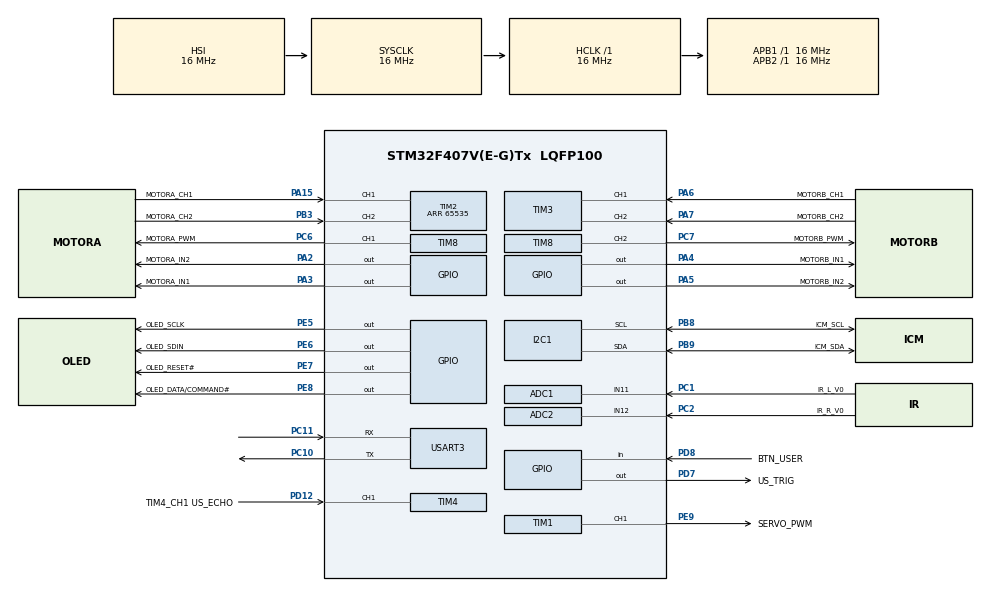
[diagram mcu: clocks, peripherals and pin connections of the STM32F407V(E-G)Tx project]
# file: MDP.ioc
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ADC1.Channel-1\#ChannelRegularConversion=ADC_CHANNEL_11
ADC1.NbrOfConversionFlag=1
ADC1.Rank-1\#ChannelRegularConversion=1
ADC1.SamplingTime-1\#ChannelRegularConversion=ADC_SAMPLETIME_3CYCLES
ADC1.master=1
ADC2.Channel-1\#ChannelRegularConversion=ADC_CHANNEL_12
ADC2.NbrOfConversionFlag=1
ADC2.Rank-1\#ChannelRegularConversion=1
ADC2.SamplingTime-1\#ChannelRegularConversion=ADC_SAMPLETIME_3CYCLES
I2C1.I2C_Mode=I2C_Fast
I2C1.NoStretchMode=I2C_NOSTRETCH_DISABLE
Mcu.Family=STM32F4
Mcu.Name=STM32F407V(E-G)Tx
Mcu.Package=LQFP100
NVIC.ADC_IRQn=true\:0\:0\:false\:false\:true\:true\:true\:true
NVIC.PriorityGroup=NVIC_PRIORITYGROUP_4
NVIC.TIM1_CC_IRQn=true\:0\:0\:false\:false\:true\:true\:true\:true
NVIC.TIM4_IRQn=true\:0\:0\:false\:false\:true\:true\:true\:true
NVIC.TIM7_IRQn=true\:0\:0\:false\:false\:true\:true\:true\:true
NVIC.USART3_IRQn=true\:0\:0\:false\:false\:true\:true\:true\:true
PA13.Signal=SYS_JTMS-SWDIO
PA14.Signal=SYS_JTCK-SWCLK
PA15.GPIO_Label=MOTORA_CH1
PA15.Signal=S_TIM2_CH1_ETR
PA2.GPIO_Label=MOTORA_IN2
PA2.Signal=GPIO_Output
PA3.GPIO_Label=MOTORA_IN1
PA3.Signal=GPIO_Output
PA4.GPIO_Label=MOTORB_IN1
PA4.Signal=GPIO_Output
PA5.GPIO_Label=MOTORB_IN2
PA5.Signal=GPIO_Output
PA6.GPIO_Label=MOTORB_CH1
PA6.Signal=S_TIM3_CH1
PA7.GPIO_Label=MOTORB_CH2
PA7.Signal=S_TIM3_CH2
PB3.GPIO_Label=MOTORA_CH2
PB3.Signal=S_TIM2_CH2
PB8.GPIO_Label=ICM_SCL
PB8.Mode=I2C
PB8.Signal=I2C1_SCL
PB9.GPIO_Label=ICM_SDA
PB9.Mode=I2C
PB9.Signal=I2C1_SDA
PC1.GPIO_Label=IR_L_V0
PC1.Signal=ADCx_IN11
PC10.Mode=Asynchronous
PC10.Signal=USART3_TX
PC11.Mode=Asynchronous
PC11.Signal=USART3_RX
PC2.GPIO_Label=IR_R_V0
PC2.Signal=ADCx_IN12
PC6.GPIO_Label=MOTORA_PWM
PC6.Signal=S_TIM8_CH1
PC7.GPIO_Label=MOTORB_PWM
PC7.Signal=S_TIM8_CH2
PD12.GPIO_Label=TIM4_CH1 US_ECHO
PD12.Signal=S_TIM4_CH1
PD7.GPIO_Label=US_TRIG
PD7.Signal=GPIO_Output
PD8.GPIO_Label=BTN_USER
PD8.GPIO_PuPd=GPIO_PULLUP
PD8.Signal=GPIO_Input
PE5.GPIO_Label=OLED_SCLK
PE5.Signal=GPIO_Output
PE6.GPIO_Label=OLED_SDIN
PE6.Signal=GPIO_Output
PE7.GPIO_Label=OLED_RESET\#
PE7.Signal=GPIO_Output
PE8.GPIO_Label=OLED_DATA/COMMAND\#
PE8.Signal=GPIO_Output
PE9.GPIO_Label=SERVO_PWM
PE9.Signal=S_TIM1_CH1
ProjectManager.HeapSize=0x200
ProjectManager.StackSize=0x400
ProjectManager.TargetToolchain=STM32CubeIDE
RCC.AHBFreq_Value=16000000
RCC.APB1Freq_Value=16000000
RCC.APB2Freq_Value=16000000
RCC.APB2TimFreq_Value=16000000
RCC.CortexFreq_Value=16000000
RCC.HSE_VALUE=25000000
RCC.HSI_VALUE=16000000
RCC.LSE_VALUE=32768
RCC.SYSCLKFreq_VALUE=16000000
RCC.VCOOutputFreq_Value=192000000
SH.ADCx_IN11.0=ADC1_IN11,IN11
SH.ADCx_IN12.0=ADC2_IN12,IN12
SH.S_TIM1_CH1.0=TIM1_CH1,PWM Generation1 CH1
SH.S_TIM2_CH1_ETR.0=TIM2_CH1,Encoder_Interface
SH.S_TIM2_CH2.0=TIM2_CH2,Encoder_Interface
SH.S_TIM3_CH1.0=TIM3_CH1,Encoder_Interface
SH.S_TIM3_CH2.0=TIM3_CH2,Encoder_Interface
SH.S_TIM4_CH1.0=TIM4_CH1,Input_Capture1_from_TI1
SH.S_TIM8_CH1.0=TIM8_CH1,PWM Generation1 CH1
SH.S_TIM8_CH2.0=TIM8_CH2,PWM Generation2 CH2
TIM1.Channel-PWM\ Generation1\ CH1=TIM_CHANNEL_1
TIM1.CounterMode=TIM_COUNTERMODE_UP
TIM1.OCMode_PWM-PWM\ Generation1\ CH1=TIM_OCMODE_PWM1
TIM1.Period=64000-1
TIM1.Prescaler=5-1
TIM2.EncoderMode=TIM_ENCODERMODE_TI12
TIM2.IC1Polarity=TIM_ICPOLARITY_RISING
TIM2.IC2Polarity=TIM_ICPOLARITY_RISING
TIM2.Period=65535
TIM3.EncoderMode=TIM_ENCODERMODE_TI12
TIM3.IC1Filter=0
TIM3.IC1Polarity=TIM_ICPOLARITY_RISING
TIM3.IC2Filter=0
TIM3.IC2Polarity=TIM_ICPOLARITY_RISING
TIM4.Channel-Input_Capture1_from_TI1=TIM_CHANNEL_1
TIM4.Period=65536-1
TIM4.Prescaler=16-1
TIM6.Period=65536-1
TIM6.Prescaler=16-1
TIM7.Period=16000-1
TIM7.Prescaler=2-1
TIM8.Channel-PWM\ Generation1\ CH1=TIM_CHANNEL_1
TIM8.Channel-PWM\ Generation2\ CH2=TIM_CHANNEL_2
TIM8.Period=7200-1
USART3.VirtualMode=VM_ASYNC
VP_TIM1_VS_ClockSourceINT.Mode=Internal
VP_TIM4_VS_ClockSourceINT.Mode=Internal
VP_TIM6_VS_ClockSourceINT.Mode=Enable_Timer
VP_TIM7_VS_ClockSourceINT.Mode=Enable_Timer
VP_TIM8_VS_ClockSourceINT.Mode=Internal
board=custom

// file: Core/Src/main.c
/* USER CODE BEGIN Header */
/**
  ******************************************************************************
  * @file           : main.c
  * @brief          : Main program body
  ******************************************************************************
  * @attention
  *
  * Copyright (c) 2024 STMicroelectronics.
  * All rights reserved.
  *
  * This software is licensed under terms that can be found in the LICENSE file
  * in the root directory of this software component.
  * If no LICENSE file comes with this software, it is provided AS-IS.
  *
  ******************************************************************************
  */
/* USER CODE END Header */
#include "main.h"

/* USER CODE BEGIN Includes */
#include <stdlib.h>
#include <math.h>
#include "commands.h"
#include "dist.h"
#include "angle.h"
#include "delay_us.h"
#include "oled.h"
#include "sensors.h"
#include "motor.h"
#include "servo.h"
/* USER CODE END Includes */

/* USER CODE BEGIN PD */
//8MHz / 16000 = 2.0ms frame.
#define MS_FRAME 2.0f
#define SERIAL_BUF_SIZE 20
#define SERIAL_RING_SIZE 1000
#define DIST_DIFF_DEFAULT 50
#define BRAKE_SPEED 20
#define TICKS_ES_MAX 10
#define PI 3.14159265359
#define DEG_TO_RAD 180 / PI
/* USER CODE END PD */

ADC_HandleTypeDef hadc1;
ADC_HandleTypeDef hadc2;

I2C_HandleTypeDef hi2c1;

TIM_HandleTypeDef htim1;
TIM_HandleTypeDef htim2;
TIM_HandleTypeDef htim3;
TIM_HandleTypeDef htim4;
TIM_HandleTypeDef htim6;
TIM_HandleTypeDef htim7;
TIM_HandleTypeDef htim8;

UART_HandleTypeDef huart3;

/* USER CODE BEGIN PV */
//sensors variables.
Sensors sensors;
MagCalParams magCalParams;

//serial buffers.
volatile uint16_t ring_i = 0, track_i = 0;
uint16_t buf_i = 0;

uint8_t buf_serial[SERIAL_BUF_SIZE];
uint8_t ring_serial[SERIAL_RING_SIZE];

//ultrasound pulse width measurement.
volatile uint8_t isRisingCaptured = 0;
volatile uint8_t usCaptureComplete = 0;
volatile uint16_t usWrap = 0;
volatile uint32_t counter;

//paced loop.
volatile uint8_t newTick = 0;
/* USER CODE END PV */

void SystemClock_Config(void);
static void MX_GPIO_Init(void);
static void MX_USART3_UART_Init(void);
static void MX_I2C1_Init(void);
static void MX_TIM8_Init(void);
static void MX_TIM2_Init(void);
static void MX_TIM3_Init(void);
static void MX_TIM1_Init(void);
static void MX_TIM4_Init(void);
static void MX_ADC1_Init(void);
static void MX_TIM6_Init(void);
static void MX_TIM7_Init(void);
static void MX_ADC2_Init(void);

/* USER CODE BEGIN 0 */

//increment index in a ring.
static void serial_inc_ring(volatile uint16_t *i) {
	*i = (*i + 1) % SERIAL_RING_SIZE;
}

//serial in.
void HAL_UART_RxCpltCallback(UART_HandleTypeDef *huart) {
	serial_inc_ring(&ring_i);
	HAL_UART_Receive_IT(&huart3, &ring_serial[ring_i], 1);
}

/* --- Start: Timer Management --- */
void HAL_TIM_PeriodElapsedCallback(TIM_HandleTypeDef *htim) {
	if (htim == &htim4) {
		usWrap++;
	}

	else if (htim == &htim7) {
		newTick = 1;
	}
}
void HAL_TIM_IC_CaptureCallback(TIM_HandleTypeDef *htim) {
	if (htim != &htim4) return;

	if (!isRisingCaptured) {
		//rising edge
		usCaptureComplete = 0;

		usWrap = 0;
		__HAL_TIM_SET_COUNTER(htim, 0);

		isRisingCaptured = 1;
		__HAL_TIM_SET_CAPTUREPOLARITY(htim, US_IC_CHANNEL, TIM_INPUTCHANNELPOLARITY_FALLING);
	} else {
		//falling edge
		counter = HAL_TIM_ReadCapturedValue(htim, US_IC_CHANNEL);
		counter += usWrap * 65536;
		sensors_read_usDist((float) counter * 1e-6);

		isRisingCaptured = 0;
		__HAL_TIM_SET_CAPTUREPOLARITY(htim, US_IC_CHANNEL, TIM_INPUTCHANNELPOLARITY_RISING);

		usCaptureComplete = 1;
	}
}
/* --- End: Timer Management --- */

/* USER CODE END 0 */

int main(void)
{

  /* USER CODE BEGIN 1 */
  uint8_t clear[100] = {0};
  /* USER CODE END 1 */

  /* MCU Configuration--------------------------------------------------------*/

  /* Reset of all peripherals, Initializes the Flash interface and the Systick. */
  HAL_Init();

  /* Configure the system clock */
  SystemClock_Config();

  /* Initialize all configured peripherals */
  MX_GPIO_Init();
  MX_USART3_UART_Init();
  MX_I2C1_Init();
  MX_TIM8_Init();
  MX_TIM2_Init();
  MX_TIM3_Init();
  MX_TIM1_Init();
  MX_TIM4_Init();
  MX_ADC1_Init();
  MX_TIM6_Init();
  MX_TIM7_Init();
  MX_ADC2_Init();
  /* USER CODE BEGIN 2 */

  /* ----- Start: Initialize libraries ----- */
  OLED_Init();												//initialize OLED display.
  magcal_init(&hi2c1, &magCalParams);						//initialize magnetometer calibration.
  motion_sen_init(&hi2c1, &hadc1, &hadc2, &htim4, &sensors); 	//initialize motion sensors.
  motor_init(&htim8, &htim2, &htim3); 						//initialize motor PWM and encoders.
  servo_init(&htim1); 										//initialize servo PWM.
  delay_us_init(&htim6);											//initialize us timer.

  dist_track_init();												//initialize distance tracking.
  /* ----- End: Initialize libraries ----- */

  /* ----- Start: Car setup ----- */
//  magcal_calc_params();

  //reset car.
  servo_setAngle(0);
  motor_setDrive(0, 0);
  //magcal_calc_params(); //Magcal prep to fix bias

  OLED_ShowString(0, 0, "Press USER when ready...");
  OLED_Refresh_Gram();
  while (!user_is_pressed());	//wait for user to place car.
  HAL_Delay(1000);
  servo_setAngle(0);
  OLED_Clear();
  OLED_ShowString(0, 0, "Calibrating...");
  OLED_Refresh_Gram();

  sensors_set_bias(5000); 		// set initial bias. 625 was working for us
  //sensors_set_bias(500);
  //HAL_Delay(500);

  OLED_ShowString(0, 0, "Calibration done.");
  OLED_Refresh_Gram();

  /* ----- End: Car setup ----- */

  /* ----- Start: OS Parameters ----- */
  //ticking for longer timing requirements for ultrasound, and servo turning.
  uint8_t ticksElapsed = 0,
		  ticksUsElapsed = 0,
		  ticksUs = (uint8_t) (US_MIN_DELAY / MS_FRAME) + 1,
		  ticksServo = (uint8_t) (SERVO_TURN_PERIOD / MS_FRAME),
		  ticksServoFull = (uint8_t) (SERVO_TURN_PERIOD * SERVO_WIDTH / SERVO_TURN_STEP) / MS_FRAME,
		  ticksMotor = (uint8_t) (MOTOR_CORRECTION_PERIOD / MS_FRAME),
		  ticksRefresh = lcm_uint8(lcm_uint8(ticksUs, ticksServo), ticksMotor),
		  ticksDelay = ticksServoFull - 1;

  //ticking for error stabilization.
  uint8_t ticksES = 0;

  Command *cmd = NULL;							//current command.
  float angleToSteer = 0;						//current steering angle.
  float motorDist = 0, estDist = 0, estAngle = 0, estDistOld = 0; 	//distance estimations.

  //for distance tracking (for use with INFO_DIST command).
  float distTrack = 0;
  volatile uint8_t shouldTrackDist = 0;			//This is the binary to check

  float distTarget = 0;							//decide distance target.
  float distDiff = 0, brakingDist = 0; 			//current distance difference.
  float distDiffOld = 0;						//track old distance difference (to see if stationary).
  float wDiff = 0, wTarget = 0;					//current angular velocity difference and target.
  float rBack = 0, rRobot = 0;					//turning radii at the back and centre of robot.

  uint32_t lastOLEDUpdate = 0;
  /* ----- End: OS Parameters ----- */

  /* ----- Start: Interrupts ----- */
  HAL_UART_Receive_IT(&huart3, &ring_serial[ring_i], 1);	//start receiving serial.
  HAL_TIM_Base_Start_IT(&htim7);							//start paced loop timer.
  /* ----- End: Interrupts ----- */

  OLED_Clear();
  OLED_ShowString(0, 0, "Active.");
  OLED_Refresh_Gram();

  char uart_msg[128];  // Buffer for UART message
  float gyro_bearing = 0;
  float gyroZ = 0;
  float last_time = 0;
  float GYRO_HPF_FREQ = 0.16;

  float gyro_drift_dps = 0;

  // 'frame_0_delay-0', 128x64px
  const uint8_t frame0[] = {  	0xd2, 0xff, 0xff, 0x8e, 0xe7, 0xff, 0x72, 0xb9, 0xfe, 0xe6, 0xef, 0x9f, 0xd5, 0xde, 0x98, 0x00,
  	0x7a, 0x3a, 0x83, 0xc1, 0xc3, 0x31, 0x3a, 0x47, 0xb3, 0xf1, 0xd3, 0xd0, 0xc0, 0x86, 0x40, 0xff,
  	0x7f, 0xa5, 0x20, 0x74, 0xbc, 0xe9, 0xed, 0xee, 0xe9, 0xac, 0xaf, 0xeb, 0xe7, 0x86, 0xeb, 0xe3,
  	0xd7, 0xf7, 0x37, 0x1a, 0xdf, 0xd8, 0xa1, 0x82, 0x67, 0x3f, 0xaf, 0x46, 0x08, 0xb5, 0x69, 0x8f,
  	0xb7, 0x0e, 0x72, 0xf0, 0xd7, 0xb8, 0x78, 0x78, 0xc8, 0x70, 0xde, 0xfd, 0xe5, 0x0d, 0x38, 0x26,
  	0x2f, 0xa1, 0xd2, 0xf8, 0xe8, 0x30, 0x60, 0x9e, 0x6a, 0x85, 0x86, 0x8f, 0xc3, 0x0f, 0x7a, 0x2f,
  	0x97, 0x43, 0xcb, 0xe1, 0xd1, 0x43, 0x77, 0x27, 0x3f, 0xbc, 0xfc, 0xc3, 0x31, 0x04, 0x7e, 0x24,
  	0x16, 0x91, 0xc5, 0xe1, 0x74, 0xb8, 0xbc, 0x31, 0xbd, 0xbc, 0x84, 0x70, 0xe1, 0xf9, 0xfa, 0x41,
  	0x4d, 0x6c, 0xfe, 0x59, 0x7d, 0xff, 0x08, 0x77, 0x67, 0x73, 0x6d, 0x19, 0xfb, 0xf8, 0x7d, 0x7b,
  	0xbf, 0x1f, 0x0d, 0xcc, 0x8c, 0xc8, 0xc0, 0x40, 0xfd, 0x9f, 0xdd, 0x95, 0x2d, 0xdd, 0x98, 0xff,
  	0xed, 0xf9, 0x49, 0xf7, 0xe3, 0x0e, 0x04, 0xf4, 0xe0, 0x27, 0x34, 0xea, 0x20, 0x71, 0xef, 0xef,
  	0x67, 0x0f, 0xbf, 0x0b, 0x19, 0x1b, 0x18, 0xf8, 0xfe, 0x8e, 0xb3, 0x07, 0xc0, 0xc5, 0x37, 0x3f,
  	0x43, 0x7f, 0xfe, 0xfc, 0x67, 0xf9, 0x8f, 0xbf, 0x8f, 0x76, 0xe0, 0xff, 0xeb, 0x09, 0xff, 0xfb,
  	0xfd, 0x35, 0x40, 0xfc, 0x46, 0x1f, 0xff, 0xce, 0x02, 0xc7, 0x87, 0xe1, 0xd3, 0xf7, 0xf9, 0x78,
  	0x94, 0x1b, 0x3f, 0x89, 0xbe, 0x9b, 0x5d, 0x2c, 0x30, 0x18, 0x19, 0x98, 0x7d, 0x72, 0xde, 0xde,
  	0x9f, 0xef, 0xfe, 0xef, 0xfe, 0xc2, 0x1d, 0x3b, 0x10, 0xa1, 0x20, 0xe0, 0xef, 0xe4, 0x6d, 0xc7,
  	0x58, 0xfc, 0xf9, 0x7c, 0x5d, 0x6b, 0xd9, 0xa8, 0x00, 0x64, 0xfc, 0xfc, 0x7f, 0x3d, 0x00, 0x00,
  	0x9a, 0xef, 0xef, 0x5f, 0x1f, 0xd7, 0x1c, 0x3f, 0xff, 0x0f, 0x7f, 0xfb, 0xb6, 0x25, 0x87, 0x1f,
  	0xd6, 0xa7, 0x8e, 0x79, 0xe8, 0xc7, 0xcf, 0x9f, 0xf4, 0xf8, 0x67, 0xe7, 0xc7, 0xef, 0xfc, 0x49,
  	0x00, 0xdb, 0xdb, 0x42, 0x98, 0xee, 0x42, 0x4d, 0x0f, 0x8c, 0x0f, 0x09, 0x23, 0xe3, 0xf4, 0xc9,
  	0x60, 0x60, 0x7f, 0xfe, 0x7e, 0x79, 0x9f, 0x36, 0x1f, 0xd8, 0x99, 0x39, 0x80, 0x6f, 0x3c, 0x7e,
  	0xfd, 0x1c, 0xf2, 0x39, 0x1d, 0x3c, 0x83, 0xe7, 0xe8, 0x81, 0x31, 0xfb, 0xff, 0xf3, 0x4b, 0x03,
  	0xe5, 0xec, 0x97, 0xdb, 0x12, 0x81, 0x87, 0xbf, 0x17, 0x90, 0xc0, 0x31, 0xb4, 0xbf, 0x3b, 0x25,
  	0xe6, 0xbf, 0x7f, 0x01, 0xf7, 0xa7, 0xf1, 0x7c, 0x5c, 0xf5, 0xef, 0xf9, 0xa0, 0xf9, 0xf4, 0xf9,
  	0xf7, 0xdf, 0x1b, 0xf1, 0xe5, 0x05, 0x68, 0x7d, 0x79, 0xf9, 0xa1, 0xc8, 0xcc, 0x24, 0xfc, 0x7f,
  	0xfd, 0xff, 0xb9, 0xe8, 0xae, 0x1f, 0xf8, 0x29, 0x1d, 0x2c, 0x3c, 0xe8, 0x02, 0xfb, 0xfb, 0x00,
  	0xc3, 0xe3, 0xf9, 0xfb, 0x03, 0x00, 0xc0, 0xf1, 0x79, 0x19, 0x0b, 0x3a, 0xf1, 0xe3, 0x03, 0x03,
  	0x00, 0x01, 0x00, 0x23, 0x33, 0x1b, 0x09, 0x9a, 0xf1, 0x62, 0x01, 0x03, 0xf9, 0xfa, 0x03, 0x81,
  	0xe0, 0xf3, 0x18, 0x8b, 0x89, 0xfa, 0xfb, 0xf8, 0x03, 0xf3, 0xfa, 0xf2, 0x81, 0xc1, 0xe3, 0xf8,
  	0xf9, 0x02, 0x3b, 0xf9, 0xe1, 0x61, 0x62, 0xe2, 0xe0, 0xf9, 0x3b, 0x01, 0xf9, 0xf9, 0x09, 0x08,
  	0x09, 0x0b, 0x08, 0x60, 0x75, 0x0f, 0x32, 0xf9, 0xe3, 0xe4, 0xf7, 0xb7, 0x2d, 0x3f, 0xe6, 0x8a,
  	0xb2, 0x22, 0xf0, 0xf1, 0xfd, 0x5f, 0x0f, 0x07, 0xc9, 0xca, 0xe6, 0xec, 0xef, 0x31, 0xe7, 0xf3,
  	0x3b, 0x07, 0x4c, 0xed, 0xf9, 0xf0, 0x1f, 0x4e, 0x96, 0x9b, 0x50, 0x42, 0x3b, 0x70, 0xa7, 0xc5,
  	0x8f, 0xba, 0x71, 0xfb, 0xbf, 0x8f, 0x0e, 0xe6, 0x0c, 0x0f, 0xde, 0xbc, 0x80, 0xdf, 0x1f, 0xc7,
  	0xc3, 0x00, 0x1f, 0x1f, 0x80, 0x80, 0xc3, 0x07, 0x0e, 0x98, 0x18, 0x9c, 0xcf, 0xc7, 0xc0, 0xc0,
  	0xc0, 0xc0, 0xc0, 0x86, 0x8f, 0xdb, 0xd9, 0xd9, 0x0c, 0x04, 0x80, 0x80, 0x1f, 0xcf, 0x00, 0x81,
  	0xc7, 0xcf, 0x98, 0xd8, 0x58, 0xdc, 0x4e, 0x84, 0x00, 0xcf, 0xdf, 0xcf, 0xc7, 0xc3, 0x80, 0xdf,
  	0xdf, 0xc0, 0x40, 0x00, 0x03, 0x0f, 0x9e, 0xcf, 0xc3, 0x00, 0x00, 0x00, 0x1f, 0xdf, 0x80, 0x00,
  	0x40, 0x80, 0xc0, 0x13, 0x2f, 0xe9, 0x3e, 0xc6, 0xc9, 0x4d, 0xff, 0xf3, 0xff, 0x98, 0xf0, 0xb0,
  	0xb8, 0x8c, 0xbe, 0x99, 0xb9, 0xb9, 0x37, 0xa2, 0x41, 0xcf, 0xff, 0x58, 0xde, 0xae, 0xae, 0xe3,
  	0xf1, 0x75, 0xfe, 0x17, 0xae, 0xbb, 0xf7, 0x70, 0x0e, 0x8f, 0x8b, 0xfb, 0x79, 0x15, 0x4c, 0x68,
  	0xff, 0xf9, 0x91, 0x82, 0xe7, 0x2b, 0x0a, 0xef, 0x3c, 0x59, 0x3c, 0x39, 0xdf, 0xbd, 0x2b, 0x0d,
  	0x83, 0x99, 0xff, 0xc6, 0x08, 0x39, 0x73, 0x57, 0x2d, 0x24, 0xff, 0xef, 0x90, 0x20, 0xfc, 0x3c,
  	0x37, 0xc7, 0x65, 0x7f, 0xff, 0x77, 0x57, 0x14, 0xc4, 0xce, 0x7d, 0xe7, 0xe1, 0xfc, 0xa4, 0x77,
  	0x7b, 0x39, 0x1d, 0xbf, 0x9b, 0xff, 0xf6, 0x54, 0xc4, 0x1a, 0xc2, 0xa2, 0x35, 0xbb, 0x09, 0x0f,
  	0xd7, 0x1f, 0x3a, 0xf0, 0x60, 0x62, 0x0f, 0x9b, 0x1f, 0xd2, 0x12, 0xe3, 0xe3, 0xd3, 0xe3, 0xee,
  	0xfe, 0xfd, 0xf8, 0xe0, 0xe6, 0x68, 0x66, 0xa6, 0xcd, 0x01, 0x0f, 0x1e, 0xfd, 0x85, 0x37, 0x7f,
  	0x1f, 0xa7, 0x33, 0xf7, 0x78, 0x00, 0x88, 0x6b, 0x48, 0xe9, 0x77, 0x70, 0xe8, 0x99, 0xbf, 0xff,
  	0x2f, 0xf8, 0x35, 0x67, 0x8d, 0xb5, 0x91, 0xbe, 0xfc, 0xff, 0xc1, 0x3f, 0x3d, 0x20, 0xf0, 0xdd,
  	0xc4, 0xc0, 0x5d, 0x55, 0xff, 0x80, 0x2e, 0xa5, 0xa0, 0xe1, 0xbd, 0x3f, 0x81, 0xad, 0x54, 0x98,
  	0x39, 0x0c, 0xfc, 0x7c, 0x67, 0x7b, 0xf1, 0x3a, 0xb3, 0xc2, 0x60, 0xfe, 0x0c, 0xc6, 0x26, 0x2f,
  	0x16, 0x92, 0xa0, 0x18, 0x31, 0x79, 0x7e, 0xde, 0x0a, 0x58, 0x90, 0x94, 0xcc, 0xec, 0xf7, 0xc0,
  	0xac, 0xc1, 0xcf, 0x5c, 0x7c, 0x68, 0x58, 0x3f, 0x6e, 0xa0, 0x3e, 0x34, 0x05, 0x4d, 0x79, 0x32,
  	0xf3, 0xd7, 0xe1, 0x72, 0xc2, 0x62, 0xf6, 0x56, 0x1d, 0x15, 0x92, 0xe1, 0x03, 0x3b, 0xfd, 0xe9,
  	0xe4, 0x66, 0x3a, 0x81, 0xf7, 0xf7, 0x78, 0x02, 0xd7, 0xde, 0xc1, 0xc6, 0x96, 0x03, 0x4e, 0x3f,
  	0x1a, 0x33, 0x9f, 0xb2, 0x23, 0x51, 0x98, 0x83, 0xab, 0x81, 0x4f, 0x74, 0x95, 0xde, 0xca, 0x04,
  	0xb7, 0xa1, 0xdf, 0xd3, 0xc9, 0x89, 0x49, 0xcc, 0x6e, 0x7a, 0xe6, 0x86, 0x84, 0xc0, 0x9b, 0x9c,
  	0x35, 0x9d, 0x1e, 0x8f, 0xff, 0x7f, 0x5c, 0x21, 0x37, 0x41, 0xe7, 0xe6, 0x07, 0xff, 0xf9, 0xdf,
  	0x9f, 0x57, 0x63, 0x66, 0x38, 0xf1, 0xf7, 0xe7, 0x98, 0x3f, 0xe6, 0xdf, 0xcb, 0xd9, 0xc9, 0x20,
  	0x6e, 0xff, 0x7b, 0x7b, 0x53, 0x5a, 0xaf, 0x8b, 0xe8, 0xde, 0x5f, 0x08, 0x9c, 0xf1, 0x67, 0x73,
  	0xf4, 0xf1, 0xf9, 0x4b, 0x4c, 0xae, 0x0e, 0x48, 0xe0, 0xfe, 0xb8, 0xfa, 0x77, 0xf7, 0xbf, 0xfc,
  	0xfb, 0xfc, 0x8c, 0x9e, 0x7a, 0x3b, 0xbe, 0x80, 0x67, 0x2f, 0xbf, 0x63, 0x11, 0x90, 0x17, 0x57,
  	0x7c, 0x58, 0x21, 0xb8, 0x32, 0x20, 0xfc, 0xef, 0x8f, 0x84, 0x86, 0x0b, 0x9e, 0x9f, 0x81, 0xc0,
  	0x26, 0x28, 0xf9, 0xfd, 0x3a, 0x16, 0x3c, 0xbb, 0xfc, 0xec, 0xfc, 0x8f, 0x63, 0xcf, 0xd9, 0x15
  };
  // 'frame_1_delay-0', 128x64px
  const uint8_t frame1[] = {  	0x41, 0xfb, 0xfb, 0xc0, 0xf0, 0xdf, 0xbc, 0xbd, 0x31, 0xbc, 0xf8, 0x74, 0xe1, 0xc5, 0x91, 0x16,
  	0x24, 0x7e, 0x04, 0x11, 0xc3, 0xfc, 0xbc, 0x3f, 0x27, 0x77, 0x43, 0xd1, 0xe1, 0xcb, 0x43, 0x87,
  	0x2f, 0x78, 0x1f, 0xc3, 0x8f, 0x86, 0x86, 0x6a, 0x1e, 0x60, 0x30, 0xe8, 0xf8, 0xd2, 0xa1, 0x2f,
  	0x26, 0x38, 0x0d, 0xe5, 0xfd, 0xde, 0x70, 0xc0, 0x78, 0x78, 0xb8, 0xd7, 0xe0, 0x72, 0x0e, 0xb7,
  	0x8b, 0x69, 0xb5, 0x08, 0x46, 0xaf, 0x3d, 0x67, 0x82, 0xa1, 0xd8, 0xdb, 0x1a, 0x37, 0xf7, 0xd7,
  	0xe3, 0xe9, 0x86, 0xe7, 0xeb, 0xaf, 0xac, 0xe9, 0xee, 0xed, 0xe9, 0xbc, 0x74, 0x20, 0xa5, 0x7f,
  	0xff, 0x40, 0x86, 0xc0, 0xd0, 0xd3, 0xf1, 0xb3, 0x47, 0x3a, 0x31, 0xc3, 0xc1, 0x83, 0x3a, 0x7a,
  	0x00, 0x98, 0xde, 0xd5, 0x9f, 0xef, 0xe6, 0xfe, 0xbb, 0xf7, 0xbf, 0xe7, 0x8f, 0x2f, 0xef, 0xd2,
  	0xc7, 0x6f, 0xff, 0xce, 0xf4, 0x7f, 0x80, 0x10, 0x3b, 0x1d, 0xc2, 0xfe, 0xff, 0xff, 0xef, 0x9f,
  	0xde, 0xde, 0x72, 0x79, 0x98, 0x19, 0x18, 0x30, 0x2c, 0x5d, 0x9b, 0xbe, 0x89, 0x3f, 0x1b, 0x94,
  	0x78, 0xf8, 0xf7, 0xdb, 0xe1, 0x86, 0xc7, 0x02, 0xce, 0xff, 0x1f, 0x46, 0xfc, 0x40, 0x35, 0xfd,
  	0xfb, 0xff, 0x09, 0xeb, 0xff, 0xe0, 0x76, 0x8f, 0xbf, 0x8f, 0xb9, 0x67, 0xfc, 0xfe, 0x7f, 0x43,
  	0x3f, 0x37, 0xc7, 0xc0, 0x07, 0xb3, 0x8e, 0xfe, 0xf8, 0x18, 0x1b, 0x18, 0x0b, 0x9f, 0x0f, 0x67,
  	0xeb, 0xef, 0x71, 0x20, 0xea, 0x34, 0x27, 0xe0, 0xf5, 0x04, 0x0e, 0xe7, 0xf7, 0x49, 0xf9, 0xef,
  	0xff, 0x98, 0xdd, 0x2d, 0x95, 0xdd, 0x9f, 0xf9, 0x40, 0xc0, 0xc8, 0x8c, 0xcc, 0x0c, 0x1f, 0xbf,
  	0x7b, 0x7d, 0xf8, 0xfb, 0x19, 0x6d, 0x73, 0x67, 0x77, 0x08, 0x5c, 0x5c, 0x59, 0xbc, 0x6c, 0x4d,
  	0xf9, 0xf4, 0xe9, 0xa0, 0xf9, 0xef, 0xf5, 0x1c, 0x7c, 0xf1, 0xa7, 0xf7, 0x01, 0x7d, 0xbf, 0xe6,
  	0x25, 0x3b, 0x3f, 0xb4, 0x31, 0xc0, 0x90, 0x17, 0xbf, 0x87, 0x81, 0x12, 0xdb, 0x9f, 0xec, 0xe5,
  	0x03, 0x4b, 0xf3, 0xff, 0xfb, 0x31, 0x91, 0xe8, 0xe5, 0x83, 0x3c, 0x1d, 0x39, 0xf2, 0x1c, 0xfd,
  	0x7f, 0x3c, 0xef, 0x80, 0x39, 0x99, 0xd8, 0x1f, 0x36, 0x9f, 0x79, 0x7e, 0xfe, 0x7f, 0x60, 0x60,
  	0xc9, 0xf4, 0xe3, 0x63, 0x09, 0x0f, 0x8c, 0x0f, 0x4d, 0x42, 0xae, 0x98, 0x42, 0xdb, 0xdb, 0x00,
  	0x09, 0xfc, 0xef, 0x47, 0xe7, 0x67, 0xf8, 0xf4, 0x9f, 0xcf, 0xc6, 0xe8, 0x79, 0x8e, 0xa7, 0xd6,
  	0x9f, 0x87, 0x24, 0xb6, 0xff, 0x7f, 0x0f, 0xff, 0x3f, 0x1c, 0xd7, 0x1f, 0x5f, 0xef, 0xef, 0x9a,
  	0x00, 0x00, 0x3d, 0x7f, 0xfc, 0xfc, 0x64, 0x00, 0xa8, 0xcb, 0x69, 0x5c, 0x7c, 0xf9, 0xf8, 0x58,
  	0xf3, 0x67, 0x31, 0xef, 0xec, 0xe6, 0x8a, 0xc9, 0x03, 0x0f, 0x5f, 0xfd, 0xf1, 0xf0, 0x22, 0xb2,
  	0x8a, 0xe6, 0x3f, 0x2d, 0xb7, 0xf7, 0xe4, 0xe3, 0xf9, 0x33, 0x0f, 0x75, 0x60, 0xf8, 0xfb, 0x01,
  	0xc0, 0xe1, 0xf9, 0xf9, 0x01, 0x03, 0xc1, 0xf0, 0x7a, 0x1a, 0x09, 0x39, 0xf1, 0xe3, 0x02, 0x01,
  	0x00, 0x03, 0x01, 0x21, 0x32, 0x1a, 0x0b, 0x9b, 0xf0, 0x63, 0x02, 0x01, 0xfb, 0xf8, 0x03, 0x80,
  	0xe1, 0xf3, 0x1a, 0x89, 0x8b, 0xf9, 0xfa, 0xf9, 0x02, 0xf1, 0xfb, 0xf3, 0x83, 0xc0, 0xe1, 0xf8,
  	0xfb, 0x03, 0x3b, 0xf9, 0xe2, 0x63, 0x61, 0xe1, 0xe1, 0xf8, 0x38, 0x03, 0xfb, 0xf9, 0x0b, 0x0b,
  	0x08, 0x0b, 0x0b, 0xf2, 0xe8, 0x3c, 0x2c, 0x1d, 0x29, 0xf8, 0x1f, 0xae, 0xe8, 0xb9, 0xff, 0xff,
  	0x7f, 0xfc, 0x24, 0xcc, 0xcc, 0xa1, 0xf9, 0x79, 0x7d, 0x68, 0x05, 0xe1, 0xf1, 0x1b, 0xdf, 0xff,
  	0xe3, 0xae, 0xa6, 0xde, 0x58, 0xff, 0xcf, 0x40, 0xa2, 0x37, 0xb9, 0xb9, 0x99, 0xbe, 0x8c, 0xb8,
  	0xb0, 0xf8, 0x98, 0xff, 0xf3, 0xff, 0x4d, 0x89, 0xc6, 0x3e, 0xe9, 0x2f, 0x00, 0xdf, 0x9f, 0x47,
  	0x03, 0x80, 0xdf, 0x1f, 0x00, 0x00, 0x03, 0xc7, 0xce, 0x98, 0x18, 0x1c, 0x0f, 0x47, 0xc0, 0xc0,
  	0xc0, 0x80, 0xc0, 0xc6, 0xcf, 0xdb, 0xd9, 0x19, 0x8c, 0x44, 0xc0, 0xc0, 0xdf, 0x8f, 0xc0, 0xc1,
  	0x87, 0x0f, 0xd8, 0x18, 0x98, 0x9c, 0x0e, 0x04, 0xc0, 0xcf, 0xdf, 0x8f, 0x87, 0xc3, 0xc0, 0xdf,
  	0xdf, 0xc0, 0xc0, 0xc0, 0x83, 0x0f, 0x9e, 0x0f, 0x03, 0xc0, 0x80, 0x80, 0x1f, 0x1f, 0x00, 0xc0,
  	0xc0, 0x00, 0xc0, 0x86, 0xbc, 0xde, 0x0f, 0x0c, 0xe6, 0x0e, 0x8f, 0xbf, 0xfb, 0x71, 0xba, 0x8f,
  	0xc5, 0xa7, 0x74, 0x3b, 0x42, 0x52, 0x9b, 0x96, 0x4e, 0x1f, 0xf8, 0xf9, 0xed, 0x4c, 0x07, 0x3b,
  	0xff, 0xbf, 0x99, 0xe8, 0x70, 0x77, 0xe9, 0x48, 0x6b, 0x88, 0x00, 0x78, 0xf7, 0x33, 0xa7, 0x1f,
  	0x3f, 0x37, 0x85, 0xfd, 0x1e, 0x0f, 0x01, 0xcd, 0xae, 0x66, 0x68, 0xe6, 0xe0, 0xf8, 0xfd, 0xfe,
  	0xee, 0xe3, 0xf3, 0xe3, 0xe3, 0x12, 0xd2, 0x1f, 0x9b, 0x0f, 0x62, 0x60, 0xf0, 0x3a, 0x1f, 0xd7,
  	0x0f, 0x09, 0xbb, 0x35, 0xa2, 0xc2, 0x1a, 0xc4, 0x54, 0xf6, 0xff, 0x9b, 0xbf, 0x1d, 0xb9, 0x7b,
  	0x77, 0xa4, 0xfc, 0xe1, 0xe7, 0x7d, 0xce, 0xc4, 0x14, 0x57, 0x77, 0xff, 0x7f, 0x65, 0xc7, 0x37,
  	0x3c, 0xfc, 0x20, 0x90, 0xef, 0xff, 0x24, 0x6d, 0x57, 0x73, 0x39, 0x08, 0xc6, 0xff, 0x99, 0x83,
  	0x0d, 0x2b, 0xbd, 0xdf, 0x39, 0x3c, 0x59, 0x3c, 0xef, 0x0a, 0x2b, 0xe7, 0xc2, 0x91, 0xf9, 0xff,
  	0x68, 0x4c, 0x15, 0x79, 0xfb, 0x8b, 0x8f, 0x0e, 0x70, 0xf7, 0xbb, 0xae, 0x16, 0xfe, 0x75, 0xf3,
  	0x04, 0xca, 0x5e, 0x95, 0x74, 0xcf, 0x81, 0xab, 0x83, 0x98, 0x51, 0x03, 0xb2, 0x9f, 0x33, 0x1a,
  	0x3f, 0x4e, 0x03, 0x96, 0xc6, 0xc1, 0xca, 0xd7, 0x00, 0x78, 0xf7, 0xf7, 0x81, 0x3a, 0x66, 0xe4,
  	0xe9, 0xfd, 0x3b, 0x03, 0xe1, 0x92, 0x15, 0x1d, 0x57, 0xe6, 0x62, 0xc2, 0x72, 0xe1, 0xd7, 0xf3,
  	0x32, 0x79, 0x4d, 0x05, 0x36, 0x3e, 0xa0, 0x6e, 0x3f, 0x58, 0x68, 0x7c, 0x5c, 0xcd, 0xc1, 0xac,
  	0xc0, 0xf7, 0xec, 0xcc, 0x90, 0x90, 0x58, 0x0a, 0xde, 0x7e, 0x79, 0x31, 0x18, 0xa0, 0x92, 0x16,
  	0x2f, 0x26, 0xc6, 0x0c, 0xfe, 0x60, 0xc2, 0xb3, 0x3a, 0xf1, 0x7b, 0x67, 0x7c, 0xfc, 0x0c, 0x39,
  	0x9c, 0x54, 0xad, 0x81, 0x3f, 0xbd, 0xe1, 0xa0, 0xa5, 0x2e, 0x80, 0xef, 0x55, 0x1d, 0xc0, 0xc4,
  	0xdd, 0xf0, 0x20, 0x3d, 0x3f, 0xc1, 0xff, 0xfc, 0xbe, 0x91, 0xb5, 0x8d, 0x67, 0x35, 0xf8, 0x2f,
  	0x15, 0xd9, 0xcf, 0x43, 0x8f, 0xfc, 0xec, 0xfc, 0xbb, 0x3c, 0x16, 0x3a, 0xfd, 0xf9, 0x28, 0x26,
  	0xc0, 0x81, 0x9f, 0x9e, 0x0b, 0x86, 0xa4, 0x8f, 0xef, 0xfc, 0x20, 0x32, 0x98, 0x21, 0x58, 0x7c,
  	0x57, 0x17, 0x90, 0x11, 0x63, 0xbf, 0x2f, 0x67, 0x80, 0x9e, 0x3b, 0x7a, 0x9e, 0x8c, 0xfc, 0xfb,
  	0x7c, 0x7f, 0xf7, 0x77, 0xfa, 0xb8, 0xfe, 0xe0, 0x48, 0x0e, 0xae, 0x4c, 0x4b, 0xf9, 0xe1, 0xf4,
  	0x73, 0x67, 0xf1, 0x9c, 0x08, 0x5f, 0xde, 0xe8, 0x8b, 0xaf, 0x1a, 0x53, 0x7b, 0x7b, 0xff, 0x6f,
  	0x20, 0xc9, 0xd9, 0x4b, 0xdf, 0xe6, 0x3f, 0x98, 0xe7, 0xf7, 0xf1, 0x38, 0x66, 0x63, 0x57, 0x9f,
  	0xdf, 0xf9, 0xff, 0x07, 0xe6, 0xe7, 0x41, 0x37, 0x21, 0x5c, 0x7f, 0xff, 0x8f, 0x1e, 0x9d, 0x35,
  	0x9c, 0x9b, 0xc0, 0x84, 0x86, 0xc6, 0x7a, 0x6e, 0xcc, 0x49, 0x89, 0xcd, 0xd3, 0xdf, 0xa1, 0xb7
  };
  // 'frame_2_delay-0', 128x64px
  const uint8_t frame2[] = {  	0x7f, 0xfb, 0xdf, 0xf4, 0xf7, 0xff, 0x8b, 0xea, 0xef, 0x8c, 0xb4, 0xbd, 0x9d, 0xc1, 0x60, 0x61,
  	0x18, 0x1e, 0x63, 0xd9, 0xf0, 0xe9, 0xe8, 0xe0, 0xc3, 0x30, 0xff, 0xbf, 0xd2, 0xb0, 0xba, 0xde,
  	0x74, 0x76, 0xf7, 0x74, 0xd6, 0x57, 0x75, 0x73, 0xc3, 0xf5, 0xf1, 0xe9, 0xeb, 0x9b, 0x8d, 0xef,
  	0xec, 0x50, 0x40, 0x33, 0x9d, 0xd7, 0x83, 0x24, 0xda, 0xb4, 0xe4, 0xd3, 0x87, 0x2a, 0x79, 0x63,
  	0xce, 0xfc, 0xbd, 0x64, 0x38, 0x6e, 0x7f, 0x70, 0x86, 0x8e, 0x93, 0x97, 0xd0, 0x68, 0x7d, 0x74,
  	0x58, 0x98, 0x5e, 0x3d, 0x85, 0xe1, 0x87, 0xe3, 0x07, 0xdd, 0x37, 0xc3, 0xc1, 0xc5, 0xf5, 0xc8,
  	0xe1, 0xb4, 0x1b, 0x19, 0x4c, 0xfe, 0xf1, 0x00, 0x80, 0x27, 0x1b, 0x0b, 0x8b, 0xc0, 0x70, 0xba,
  	0x3e, 0x5c, 0xdc, 0x1a, 0xde, 0x52, 0x40, 0x30, 0xf9, 0xfc, 0xcd, 0xa4, 0x5e, 0x4a, 0xfb, 0x50,
  	0x88, 0x9e, 0x7f, 0x03, 0xbb, 0xff, 0x10, 0xc9, 0xfc, 0x3e, 0x3d, 0xdf, 0x8e, 0x86, 0xe6, 0xc6,
  	0xe4, 0x60, 0xa0, 0xfc, 0xcf, 0xce, 0xde, 0x16, 0xee, 0x9c, 0xff, 0xf7, 0xfc, 0x60, 0xab, 0x63,
  	0x87, 0x82, 0xfa, 0x74, 0x33, 0x1a, 0xf5, 0x90, 0xa8, 0x77, 0xf5, 0x33, 0x87, 0xdf, 0x05, 0x0c,
  	0x0d, 0x0c, 0xfc, 0xff, 0x47, 0xdb, 0x83, 0xe4, 0xe2, 0x13, 0x9f, 0x21, 0x39, 0xff, 0x7e, 0x33,
  	0xf9, 0xc5, 0x9f, 0xcf, 0x3f, 0xf0, 0xf9, 0xf5, 0x0d, 0x0f, 0x7f, 0xfc, 0x1e, 0x20, 0xfe, 0xff,
  	0x8f, 0xef, 0xcf, 0x03, 0xe1, 0xc3, 0xe0, 0xe8, 0xdb, 0xfb, 0x74, 0xb8, 0x4f, 0x17, 0xde, 0x07,
  	0xdf, 0xcf, 0x1e, 0x94, 0x98, 0x0c, 0xcc, 0xcc, 0x39, 0xbf, 0xe8, 0xcf, 0xe7, 0xff, 0xe7, 0xdf,
  	0xfe, 0xc0, 0x9f, 0x10, 0x98, 0xd4, 0x30, 0xfe, 0xf3, 0xf2, 0xb7, 0xc3, 0xd6, 0x03, 0x43, 0xfa,
  	0xb5, 0x6c, 0xf0, 0x80, 0x32, 0xff, 0x3d, 0x3f, 0x1c, 0x00, 0x80, 0xdf, 0xf7, 0xff, 0x2f, 0x0f,
  	0xeb, 0x1e, 0xdf, 0xff, 0x0f, 0x3d, 0x7f, 0x5b, 0x16, 0x83, 0x4f, 0xfb, 0xd3, 0xc7, 0x34, 0xf4,
  	0x43, 0x6f, 0xcf, 0xfa, 0xfc, 0x33, 0x53, 0xe3, 0xf7, 0xfe, 0xa4, 0x00, 0xc9, 0x6d, 0xa9, 0xcc,
  	0xdf, 0xa1, 0x27, 0xa7, 0x0e, 0x07, 0x95, 0x81, 0x71, 0xf8, 0xe5, 0x70, 0xb0, 0x37, 0x7f, 0xbf,
  	0x3c, 0x8f, 0xb3, 0x0f, 0xce, 0x4c, 0x1c, 0xc0, 0xa7, 0x1e, 0x3b, 0xfe, 0x3e, 0xf9, 0x39, 0x9c,
  	0x1e, 0x1f, 0x61, 0x70, 0x4c, 0x90, 0xf4, 0xed, 0xf7, 0xf5, 0x01, 0xe3, 0xf2, 0xc6, 0x4b, 0xc9,
  	0x80, 0xc3, 0xe7, 0x9f, 0x88, 0xe0, 0xac, 0xba, 0x9e, 0x9f, 0x19, 0x30, 0x5b, 0x4f, 0xb9, 0x92,
  	0x7b, 0xf3, 0xfc, 0x96, 0x7e, 0x73, 0x77, 0xf8, 0xe0, 0xbc, 0xf8, 0xdc, 0xd6, 0xcf, 0xc0, 0x33,
  	0x20, 0x3c, 0x3e, 0x7c, 0xf9, 0x60, 0x66, 0x84, 0xb2, 0xfe, 0xff, 0x5f, 0x7d, 0x94, 0xfc, 0xcf,
  	0xcf, 0x5c, 0x14, 0x0e, 0x9e, 0x1e, 0x7e, 0x7f, 0xff, 0x27, 0x3c, 0x1b, 0x03, 0xf8, 0xfb, 0x01,
  	0xc1, 0xe0, 0xf8, 0xfa, 0x00, 0x01, 0xc1, 0xf1, 0x79, 0x1b, 0x0b, 0x3b, 0xf1, 0xe0, 0x01, 0x03,
  	0x03, 0x02, 0x03, 0x20, 0x32, 0x1b, 0x0a, 0x99, 0xf3, 0x63, 0x00, 0x00, 0xfb, 0xf8, 0x03, 0x83,
  	0xe3, 0xf1, 0x1a, 0x89, 0x89, 0xf8, 0xfb, 0xfa, 0x02, 0xf1, 0xf8, 0xf2, 0x82, 0xc3, 0xe0, 0xf8,
  	0xfa, 0x03, 0x3b, 0xf8, 0xe0, 0x61, 0x62, 0xe0, 0xe1, 0xf9, 0x38, 0x03, 0xf9, 0xf9, 0x08, 0x09,
  	0x0b, 0x09, 0x08, 0xb1, 0xf2, 0xfe, 0x5f, 0x7d, 0x8f, 0x5f, 0xc1, 0x55, 0x33, 0xe0, 0x68, 0xe0,
  	0xfe, 0x0f, 0x07, 0x05, 0xc5, 0xe3, 0xe7, 0xf6, 0x72, 0x18, 0xf3, 0xe9, 0x52, 0x65, 0x01, 0x23,
  	0xfc, 0x1f, 0x61, 0x4a, 0x82, 0x48, 0x83, 0xb8, 0xa2, 0xc3, 0xc3, 0xff, 0xbb, 0x38, 0xb5, 0xd7,
  	0x8e, 0xa6, 0xe2, 0x06, 0x9f, 0xee, 0x9e, 0xaf, 0xfd, 0x98, 0xe4, 0xe0, 0x82, 0x9f, 0x9f, 0x87,
  	0xc3, 0xc0, 0x9f, 0x9f, 0x80, 0x80, 0xc3, 0x47, 0x0e, 0x98, 0x98, 0xdc, 0x8f, 0x87, 0xc0, 0x80,
  	0xc0, 0xc0, 0x40, 0x06, 0x0f, 0x1b, 0xd9, 0x19, 0x4c, 0x04, 0x00, 0xc0, 0xdf, 0x8f, 0xc0, 0x81,
  	0xc7, 0x0f, 0x58, 0x18, 0x98, 0xdc, 0x4e, 0xc4, 0xc0, 0xcf, 0xdf, 0x8f, 0x87, 0x03, 0x00, 0x1f,
  	0x9f, 0x00, 0xc0, 0xc0, 0x03, 0x0f, 0x9e, 0x0f, 0xc3, 0xc0, 0x80, 0x00, 0x1f, 0xdf, 0x00, 0x00,
  	0x00, 0x00, 0x40, 0xe4, 0x85, 0xfc, 0xef, 0xff, 0xdc, 0xdc, 0xf8, 0xfc, 0xdc, 0xce, 0x9e, 0x99,
  	0xfd, 0x1d, 0x11, 0xd9, 0x40, 0xef, 0x6f, 0x48, 0x4b, 0x87, 0xeb, 0xf1, 0x94, 0x3c, 0x1d, 0xed,
  	0xdf, 0xf3, 0x70, 0x07, 0xc7, 0x9d, 0xf9, 0xf9, 0x0e, 0xa4, 0xfc, 0xff, 0xf9, 0xd8, 0xc1, 0xa7,
  	0xa3, 0x07, 0xef, 0x1e, 0x7c, 0xb6, 0xad, 0xaf, 0xb8, 0x37, 0x84, 0x81, 0x59, 0x6f, 0x67, 0x84,
  	0x34, 0xb3, 0x21, 0xb5, 0x16, 0x7f, 0xe7, 0xd8, 0x20, 0x7e, 0x3e, 0x3b, 0xe3, 0x26, 0x7f, 0xff,
  	0xbf, 0x7b, 0x1e, 0xe6, 0x66, 0x7d, 0xee, 0x61, 0x6c, 0xe2, 0x3b, 0x7f, 0xdd, 0x8c, 0x9f, 0x5d,
  	0x7f, 0x7b, 0xaa, 0xc0, 0x49, 0x09, 0x51, 0x93, 0xd9, 0x0d, 0x01, 0x6f, 0x8f, 0x1f, 0xf8, 0x78,
  	0x31, 0x07, 0x4d, 0x9f, 0xfb, 0x08, 0xf3, 0xe1, 0xf9, 0xe1, 0xf7, 0x7f, 0x7f, 0xfc, 0x60, 0xf0,
  	0xa4, 0x26, 0x73, 0xd7, 0xc4, 0x01, 0x0f, 0x7f, 0xdb, 0x12, 0x33, 0x9f, 0xc7, 0x93, 0x7b, 0xf9,
  	0xb8, 0x80, 0x3c, 0x21, 0xe4, 0xe6, 0x32, 0x30, 0xd0, 0xdd, 0xdf, 0x7b, 0x7b, 0x70, 0xcb, 0xce,
  	0xb0, 0x9c, 0x7f, 0x77, 0x6b, 0x40, 0x1f, 0x9e, 0x20, 0x7a, 0x7e, 0xe6, 0x40, 0x5f, 0x29, 0xf7,
  	0x86, 0x36, 0xf6, 0xb0, 0xf0, 0x9e, 0x1f, 0xc0, 0x36, 0x92, 0xdc, 0x99, 0x06, 0xea, 0x7e, 0x63,
  	0x7b, 0xd9, 0x9f, 0xdb, 0xc3, 0x70, 0xef, 0x06, 0xc7, 0x96, 0x27, 0x0a, 0xc8, 0xd0, 0x1c, 0x94,
  	0x3c, 0x3f, 0x7f, 0x4c, 0x48, 0xc9, 0xd0, 0x66, 0xe4, 0xf7, 0xf0, 0xbe, 0xe5, 0xc6, 0xcf, 0x3c,
  	0x3c, 0x44, 0x1f, 0xb2, 0x70, 0xfa, 0x1e, 0x10, 0x8f, 0x7f, 0x10, 0xd3, 0x63, 0xfa, 0xb3, 0x4b,
  	0x61, 0x7a, 0x73, 0x0f, 0x1a, 0xcb, 0xd1, 0x43, 0x19, 0x35, 0xfc, 0xf4, 0x42, 0x3b, 0xdc, 0x51,
  	0xfb, 0x7f, 0x21, 0x83, 0xf3, 0x60, 0xe1, 0xd3, 0x83, 0x21, 0x0f, 0x17, 0x9a, 0x51, 0x9d, 0xa3,
  	0x21, 0x18, 0xc9, 0xa3, 0xb1, 0x87, 0x6f, 0x16, 0xde, 0xe7, 0xcd, 0x08, 0x47, 0x63, 0x1c, 0x1d,
  	0x41, 0x6c, 0x6c, 0x7f, 0x15, 0x62, 0xd2, 0xc0, 0xc0, 0x1a, 0xce, 0x97, 0x5f, 0x0f, 0xcf, 0xef,
  	0x7f, 0x5e, 0x30, 0x2e, 0x60, 0xe7, 0xe2, 0x87, 0xfe, 0xf9, 0xdf, 0xcf, 0x63, 0x23, 0xf2, 0x38,
  	0x59, 0xfb, 0x73, 0x58, 0x9f, 0xf7, 0x67, 0x4b, 0xec, 0xec, 0x00, 0x36, 0xfe, 0xfb, 0x3f, 0x7b,
  	0xbb, 0x87, 0xcf, 0xa8, 0xdd, 0x0f, 0x04, 0x9c, 0xf9, 0xe3, 0x3b, 0xf4, 0x72, 0xfc, 0xe6, 0x44,
  	0x97, 0x0f, 0x4a, 0x68, 0xfb, 0xfe, 0xf9, 0x35, 0xf7, 0x2f, 0x7c, 0x3f, 0xbf, 0x4c, 0x8f, 0xbb,
  	0x3f, 0xb8, 0x8e, 0x61, 0x27, 0x9f, 0xa7, 0x32, 0x58, 0x8a, 0x9b, 0x67, 0x7c, 0x60, 0x88, 0xba,
  	0x0a, 0x34, 0xf7, 0x77, 0xc8, 0xa6, 0x85, 0x9f, 0xcf, 0x01, 0xc0, 0x60, 0x14, 0x9c, 0xfd, 0x0e,
  	0x38, 0x0e, 0x8e, 0xf9, 0xfc, 0xee, 0xed, 0x4f, 0xe0, 0xc9, 0x5b, 0x0e, 0x07, 0xcf, 0xca, 0x63
  };
  // 'frame_3_delay-0', 128x64px
  const uint8_t frame3[] = {  	0x50, 0xfb, 0xfb, 0x5e, 0xb5, 0xdf, 0x7c, 0xf8, 0x30, 0x40, 0x52, 0xde, 0x1a, 0xde, 0x5c, 0x3e,
  	0xb2, 0x70, 0xc0, 0x8b, 0x8b, 0x1b, 0x27, 0x80, 0x08, 0xf1, 0xfe, 0x4c, 0x3b, 0x1b, 0xb4, 0xe1,
  	0xc8, 0xf5, 0xc5, 0xe1, 0xc3, 0x37, 0xdd, 0x07, 0xeb, 0x87, 0xe3, 0xc5, 0x3d, 0x5f, 0x98, 0x5c,
  	0x74, 0x7d, 0x68, 0xd0, 0x97, 0x93, 0xce, 0x86, 0x70, 0x7f, 0x6e, 0x7a, 0x64, 0xbd, 0xfc, 0xce,
  	0x63, 0x79, 0xea, 0x87, 0xdb, 0xe5, 0xb4, 0xda, 0x24, 0xa3, 0xd7, 0x1d, 0x33, 0x51, 0x50, 0xec,
  	0xed, 0x8d, 0x9b, 0xeb, 0xe9, 0xf1, 0xf5, 0xc3, 0x73, 0x75, 0x57, 0xd6, 0x74, 0xf7, 0x76, 0x7c,
  	0xde, 0xba, 0xb0, 0xd2, 0xbf, 0xff, 0x30, 0xc3, 0xe0, 0xe8, 0xe9, 0xf0, 0xd9, 0x43, 0x1e, 0x18,
  	0x61, 0x60, 0x41, 0x9d, 0xbd, 0xb4, 0x8c, 0xef, 0xea, 0xeb, 0xfe, 0xf7, 0xff, 0xdf, 0xf9, 0x7f,
  	0xfa, 0x5f, 0x7f, 0xc0, 0xf7, 0xff, 0xd2, 0xf3, 0xfe, 0x30, 0xd4, 0x98, 0x10, 0x1f, 0xc0, 0xfe,
  	0xff, 0xe7, 0xff, 0xe7, 0xef, 0xe9, 0xbf, 0x39, 0xcc, 0xcc, 0x0c, 0x98, 0x94, 0x1e, 0xcf, 0xdf,
  	0x47, 0xdf, 0x1f, 0x4f, 0xb8, 0x74, 0xfb, 0xdb, 0xf8, 0xe0, 0xc3, 0xe1, 0x07, 0xcf, 0xef, 0x8f,
  	0xff, 0xfe, 0x28, 0x1e, 0xfc, 0x3f, 0x0f, 0x8d, 0xf5, 0xf9, 0xf0, 0x3f, 0xcf, 0x9f, 0xc5, 0xf1,
  	0x33, 0x7e, 0xff, 0x39, 0x21, 0x9f, 0x1b, 0xe2, 0xe4, 0x83, 0xdb, 0x47, 0xff, 0xfc, 0x0c, 0x2d,
  	0x0c, 0x05, 0xdf, 0x87, 0x33, 0xf5, 0x77, 0xa8, 0x90, 0xf5, 0x18, 0x33, 0x74, 0xfa, 0x82, 0x87,
  	0x63, 0xab, 0x60, 0xfc, 0xf7, 0xff, 0x9c, 0xee, 0x36, 0xde, 0xce, 0xcf, 0xfc, 0xa0, 0x60, 0xe4,
  	0xc6, 0xe6, 0x86, 0x8e, 0xdf, 0x3d, 0x3e, 0xfc, 0xe9, 0x1c, 0x36, 0x3b, 0x33, 0x33, 0x8e, 0x88,
  	0xb3, 0xc0, 0xcf, 0xd6, 0xdf, 0xff, 0xbc, 0xe1, 0xf8, 0x77, 0x73, 0x7e, 0x96, 0xfe, 0xf3, 0x7b,
  	0x92, 0xb9, 0x4f, 0x7b, 0x30, 0x1d, 0x9f, 0x9e, 0xba, 0xac, 0xe0, 0x88, 0x9f, 0xe7, 0xd3, 0x80,
  	0xc9, 0x4b, 0xc6, 0xf2, 0xf3, 0x01, 0xf5, 0xf7, 0xfd, 0xf4, 0x90, 0x4c, 0x74, 0x61, 0x5f, 0x1e,
  	0x9c, 0x39, 0xf9, 0x3e, 0xfe, 0x3b, 0x1e, 0xa7, 0xc0, 0x1c, 0x4c, 0xce, 0x0f, 0xbb, 0x8f, 0x3c,
  	0xbf, 0x7f, 0x37, 0xb0, 0x74, 0xe5, 0xf8, 0x71, 0x81, 0x95, 0x07, 0x0e, 0xa7, 0x27, 0xa1, 0xdf,
  	0xcc, 0xa9, 0x6d, 0xc9, 0x00, 0xa4, 0xfe, 0xff, 0xe7, 0x53, 0xb3, 0xfc, 0xfa, 0xcf, 0xef, 0x43,
  	0xf4, 0x34, 0xc7, 0xc3, 0xfb, 0x4f, 0xc3, 0x16, 0x5b, 0x7f, 0x3d, 0x0f, 0xff, 0xdf, 0x1e, 0xeb,
  	0x0f, 0x2f, 0xff, 0xf7, 0xdf, 0x80, 0x00, 0x1c, 0x3f, 0x3f, 0xfe, 0x32, 0x80, 0xf0, 0x6c, 0xb5,
  	0x23, 0x01, 0x65, 0x5a, 0xe9, 0xf3, 0x18, 0x76, 0xf6, 0xe7, 0xa7, 0xc5, 0x05, 0x0f, 0x0f, 0xfe,
  	0xe0, 0x68, 0xe0, 0x33, 0x55, 0xe1, 0x5f, 0x8f, 0x75, 0x5f, 0xfe, 0xf2, 0x01, 0xf8, 0xf9, 0x03,
  	0xc1, 0xe0, 0xf9, 0xf9, 0x03, 0x00, 0xc1, 0xf1, 0x78, 0x1a, 0x09, 0x38, 0xf0, 0xe3, 0x03, 0x02,
  	0x00, 0x00, 0x03, 0x22, 0x32, 0x18, 0x09, 0x9a, 0xf2, 0x63, 0x00, 0x01, 0xf9, 0xfa, 0x01, 0x83,
  	0xe3, 0xf3, 0x18, 0x8b, 0x88, 0xf8, 0xfb, 0xfb, 0x01, 0xf2, 0xfb, 0xf2, 0x80, 0xc3, 0xe2, 0xfb,
  	0xfb, 0x03, 0x38, 0xf9, 0xe3, 0x63, 0x63, 0xe1, 0xe1, 0xfb, 0x39, 0x00, 0xfa, 0xf8, 0x08, 0x08,
  	0x09, 0x0b, 0x08, 0x73, 0x1b, 0x3c, 0x27, 0xff, 0x7f, 0x7e, 0x1e, 0x9e, 0x0e, 0x14, 0x5c, 0xcf,
  	0xcf, 0xfc, 0x94, 0x7d, 0x5f, 0xff, 0xfe, 0xb2, 0x84, 0x64, 0x60, 0xf8, 0x7c, 0x3e, 0x3c, 0x20,
  	0xed, 0x1d, 0x3c, 0x94, 0xf1, 0xeb, 0x87, 0x4b, 0x48, 0xef, 0xef, 0x40, 0xd9, 0x11, 0x1d, 0xfd,
  	0x99, 0x9f, 0xce, 0xdc, 0xfc, 0xf8, 0xdc, 0xdc, 0xff, 0xef, 0xfc, 0x85, 0xc4, 0x5f, 0x1f, 0x07,
  	0x03, 0x00, 0xdf, 0x1f, 0x00, 0x80, 0xc3, 0xc7, 0x0e, 0x98, 0x18, 0x1c, 0xcf, 0xc7, 0x00, 0x80,
  	0x00, 0x00, 0x00, 0xc6, 0x8f, 0xdb, 0xd9, 0xd9, 0xcc, 0x44, 0xc0, 0x80, 0x1f, 0x4f, 0x00, 0xc1,
  	0x87, 0xcf, 0x98, 0xd8, 0xd8, 0x1c, 0x0e, 0x44, 0x00, 0xcf, 0x9f, 0x0f, 0x07, 0x43, 0xc0, 0xdf,
  	0x9f, 0xc0, 0x80, 0x80, 0xc3, 0x8f, 0x9e, 0x0f, 0x43, 0xc0, 0x80, 0x80, 0x9f, 0x9f, 0xc0, 0xc0,
  	0x80, 0x80, 0x80, 0x8e, 0xe4, 0xe4, 0x98, 0xfd, 0xaf, 0x9e, 0xee, 0x9f, 0x06, 0xe2, 0x26, 0x8e,
  	0xd7, 0xb5, 0xb8, 0xba, 0xff, 0xe3, 0xc3, 0xa3, 0xb8, 0x83, 0x48, 0x80, 0x4a, 0x61, 0x1f, 0xfc,
  	0xce, 0xcb, 0xf8, 0x7b, 0x7b, 0xdf, 0xdd, 0xd0, 0x30, 0x33, 0xff, 0xe4, 0x21, 0x3c, 0x80, 0xb8,
  	0xf9, 0x7b, 0x93, 0xc7, 0x9f, 0x33, 0x12, 0xdb, 0x7f, 0x0f, 0x01, 0xc4, 0xd7, 0x73, 0x26, 0xb4,
  	0xf0, 0x60, 0xfc, 0x7f, 0x7f, 0xf7, 0xe1, 0xf9, 0xe1, 0xf3, 0x08, 0xfb, 0x8f, 0x0d, 0x07, 0x31,
  	0x78, 0xf8, 0x1f, 0x8f, 0x6f, 0x01, 0x1d, 0xd1, 0x93, 0x51, 0x09, 0x48, 0xe0, 0xaa, 0x7f, 0x7f,
  	0x5d, 0x9f, 0x8c, 0xdd, 0x7f, 0x3b, 0xe2, 0x6c, 0x61, 0xee, 0x7d, 0x66, 0xe6, 0x1e, 0x7b, 0xbf,
  	0xff, 0x7f, 0x26, 0xe3, 0x3b, 0xbe, 0x7e, 0x20, 0xd8, 0x77, 0x7f, 0x36, 0xb5, 0x21, 0xb3, 0x34,
  	0x84, 0x67, 0x6f, 0x59, 0x81, 0x84, 0x37, 0xb8, 0xaf, 0xbd, 0xb6, 0x7c, 0x1e, 0xef, 0x27, 0xa3,
  	0xa7, 0xe3, 0xd8, 0xf9, 0xff, 0xfc, 0xa4, 0x0e, 0xf9, 0xf9, 0x9d, 0xc7, 0x07, 0x74, 0xf3, 0xdf,
  	0x1d, 0x1c, 0x67, 0x47, 0x0c, 0xcd, 0xe7, 0xde, 0x56, 0x6f, 0x87, 0xb1, 0xa3, 0xc9, 0x18, 0x21,
  	0xa3, 0x9d, 0x51, 0x9a, 0x17, 0x0f, 0x21, 0x83, 0xd3, 0x61, 0x60, 0xf3, 0x83, 0x21, 0x7f, 0xfb,
  	0x51, 0xdc, 0x3b, 0x62, 0xf4, 0xfd, 0x35, 0x19, 0x43, 0xd1, 0xcb, 0x18, 0x0f, 0x73, 0x7a, 0x61,
  	0x4b, 0xb3, 0xf8, 0x63, 0xd3, 0x12, 0x7d, 0x8f, 0x90, 0x1e, 0xfe, 0x60, 0xb2, 0x1f, 0x44, 0x7c,
  	0x3c, 0xcf, 0xc6, 0xe5, 0xfe, 0xf0, 0xf7, 0xe4, 0x66, 0xd0, 0xd9, 0x48, 0x4c, 0x7f, 0x3f, 0x3c,
  	0x94, 0x1c, 0xd0, 0xc9, 0x0b, 0x27, 0x96, 0xc7, 0x06, 0xef, 0x70, 0xc3, 0xdb, 0x9f, 0xd9, 0x7b,
  	0x23, 0x7e, 0xea, 0x06, 0xb9, 0xdc, 0x92, 0x36, 0xc0, 0x1f, 0x9e, 0xf0, 0xb0, 0xf6, 0x36, 0x86,
  	0xff, 0x29, 0x5f, 0x40, 0xe6, 0x5e, 0x3a, 0x20, 0x9e, 0x1f, 0x40, 0x6b, 0x77, 0x7f, 0x98, 0xb0,
  	0x67, 0xca, 0xcf, 0x0f, 0x1e, 0x5b, 0xc9, 0xe0, 0x4f, 0xed, 0xee, 0xfc, 0xfd, 0x8e, 0x1e, 0x38,
  	0x0e, 0xfd, 0x9c, 0x14, 0x60, 0xc0, 0x01, 0xcf, 0x9f, 0x85, 0xa6, 0xc8, 0x77, 0xf7, 0x34, 0x0a,
  	0xba, 0x88, 0x60, 0x7c, 0x6f, 0x9b, 0xcb, 0xd8, 0x32, 0xa7, 0x9f, 0x27, 0x61, 0x8e, 0xb8, 0x3f,
  	0xbb, 0x8f, 0x4c, 0xbf, 0x3f, 0x7c, 0x2f, 0xf7, 0x37, 0xf9, 0xfe, 0xfb, 0x60, 0x4a, 0x0f, 0x97,
  	0x44, 0x66, 0xfc, 0x73, 0xf4, 0x3b, 0xe3, 0xf9, 0x9c, 0x04, 0x0f, 0xdd, 0xa8, 0xcf, 0x87, 0xbb,
  	0x7b, 0x3f, 0xfb, 0xfe, 0x36, 0x10, 0xec, 0xec, 0x4b, 0x67, 0xf7, 0xbf, 0xd8, 0x73, 0xfb, 0x59,
  	0x38, 0xf2, 0x33, 0x63, 0xcf, 0xdf, 0xf9, 0xff, 0xa7, 0xe2, 0xe7, 0x60, 0x2e, 0x30, 0x5e, 0x7f,
  	0xef, 0xcf, 0x8f, 0xdf, 0x9f, 0xce, 0x1a, 0xc0, 0xc4, 0xd2, 0x66, 0x15, 0x7f, 0x6c, 0x6c, 0x41
  };
  // 'frame_4_delay-0', 128x64px
  const uint8_t frame4[] = {  	0xae, 0xff, 0xff, 0x01, 0xd1, 0xff, 0x36, 0x07, 0x82, 0x86, 0x72, 0x29, 0x2f, 0xe3, 0xe3, 0xa6,
  	0x80, 0x80, 0x01, 0xc1, 0xfe, 0xbf, 0x42, 0xe0, 0x49, 0xf9, 0xd2, 0xfb, 0xdc, 0x53, 0x59, 0x5f,
  	0xd7, 0x0e, 0x0e, 0xd7, 0xe7, 0xad, 0xef, 0x6d, 0x35, 0xb7, 0xb1, 0x43, 0x04, 0xcf, 0x5a, 0x4e,
  	0x8c, 0x10, 0x6a, 0xd2, 0x1f, 0x6e, 0x1d, 0xe5, 0xe1, 0xae, 0x79, 0xf1, 0xf5, 0x90, 0xe0, 0xbd,
  	0xfb, 0xc3, 0x1a, 0x78, 0x4c, 0x5e, 0x42, 0xa4, 0xf4, 0xd1, 0x70, 0xc0, 0x7e, 0xf5, 0x17, 0x8d,
  	0x1f, 0x87, 0x1e, 0x76, 0xde, 0x0f, 0x86, 0x97, 0xc6, 0xa3, 0x84, 0xff, 0x6f, 0x6f, 0x38, 0xf9,
  	0xc5, 0xa3, 0x03, 0x9c, 0x68, 0x3c, 0x2f, 0x8b, 0xc3, 0xe9, 0xf9, 0x79, 0x71, 0x6b, 0x7e, 0x49,
  	0x01, 0xc1, 0xe3, 0xf2, 0x31, 0xd1, 0x7b, 0x82, 0xed, 0x43, 0x2f, 0x6e, 0xa6, 0xf2, 0xe6, 0x8e,
  	0x63, 0x37, 0xff, 0xca, 0xf6, 0x7f, 0x0a, 0x99, 0x09, 0x19, 0x94, 0x80, 0x81, 0xfb, 0x2f, 0xbb,
  	0x7f, 0xdb, 0xbb, 0x7b, 0xde, 0xdb, 0xe3, 0x9a, 0xee, 0xdf, 0x1d, 0x0d, 0xe1, 0xd1, 0x6f, 0x61,
  	0xd5, 0x41, 0xaf, 0xdf, 0xdf, 0x4f, 0x1f, 0x3e, 0x16, 0x31, 0x37, 0x31, 0xf1, 0xff, 0x1c, 0x67,
  	0x0e, 0x80, 0x8f, 0x6e, 0x7f, 0x87, 0xff, 0xfc, 0xf9, 0xcf, 0xf7, 0x1e, 0x7e, 0x1f, 0xec, 0xc1,
  	0xff, 0xd7, 0x12, 0xfe, 0xf6, 0xfa, 0x7b, 0x81, 0xf9, 0xdd, 0x3d, 0xbe, 0x3d, 0x04, 0x9f, 0x0f,
  	0x83, 0xa3, 0x6e, 0xeb, 0xd8, 0xa1, 0x3e, 0x7f, 0x37, 0x7d, 0x3e, 0xbe, 0x78, 0x50, 0x21, 0x33,
  	0x33, 0xf2, 0xe6, 0xfc, 0xac, 0x3e, 0xdf, 0xff, 0x9d, 0xfe, 0xfc, 0x01, 0x7e, 0x40, 0x63, 0x51,
  	0xc1, 0xd9, 0xc7, 0xcb, 0xdf, 0x0a, 0xd9, 0x0d, 0x1f, 0xe1, 0xec, 0xd6, 0x9f, 0xf5, 0x1d, 0x9b,
  	0xdd, 0xff, 0x73, 0x02, 0x31, 0x5f, 0xde, 0xbe, 0xbf, 0x1f, 0xbf, 0x7b, 0x7e, 0xff, 0x7f, 0xf7,
  	0xef, 0x6c, 0x5f, 0x1e, 0xfd, 0x8f, 0x4f, 0x79, 0xd3, 0xc1, 0x0e, 0xbe, 0xfd, 0xf9, 0xf0, 0xcf,
  	0x8f, 0x9e, 0xde, 0xf9, 0x33, 0x00, 0xb6, 0xb6, 0xa4, 0x3c, 0xdc, 0x84, 0x9f, 0x5f, 0x39, 0x1f,
  	0x12, 0xc7, 0xc7, 0xf8, 0x96, 0xc0, 0xc0, 0xff, 0xfd, 0xfc, 0xf3, 0x3f, 0x6f, 0x3f, 0xb0, 0x33,
  	0x73, 0x03, 0x9e, 0x78, 0xec, 0xfb, 0xb8, 0xe4, 0xf7, 0x7a, 0x78, 0x2f, 0xc7, 0xd0, 0x33, 0x42,
  	0xf3, 0xff, 0xef, 0x97, 0x06, 0xcb, 0xc9, 0x3c, 0x2f, 0x35, 0x03, 0x0f, 0x9c, 0x6e, 0x22, 0x00,
  	0xb3, 0xe8, 0x7c, 0x67, 0x7f, 0xc1, 0x6f, 0x3f, 0x07, 0xcb, 0xef, 0xcf, 0xf8, 0x48, 0xfb, 0xdf,
  	0xd8, 0x61, 0xd3, 0xf1, 0xe2, 0x7f, 0x5b, 0xac, 0x0f, 0xc7, 0x8e, 0x3e, 0xdf, 0xb7, 0xbf, 0xb9,
  	0x98, 0x10, 0xc8, 0xf8, 0xff, 0xff, 0xf7, 0x53, 0xfc, 0x3c, 0x3f, 0x70, 0x13, 0x3b, 0x78, 0x78,
  	0xfd, 0xfd, 0xfe, 0xb7, 0xf5, 0xef, 0xce, 0x43, 0xec, 0xc7, 0x75, 0xf3, 0x83, 0xf9, 0xfb, 0x00,
  	0xc1, 0xe2, 0xfb, 0xfb, 0x02, 0x00, 0xc3, 0xf1, 0x7a, 0x1b, 0x0b, 0x3a, 0xf0, 0xe2, 0x01, 0x00,
  	0x02, 0x02, 0x01, 0x23, 0x33, 0x19, 0x0a, 0x98, 0xf3, 0x62, 0x00, 0x03, 0xf8, 0xf8, 0x03, 0x81,
  	0xe0, 0xf3, 0x1a, 0x88, 0x88, 0xfb, 0xf8, 0xfb, 0x00, 0xf2, 0xf8, 0xf1, 0x81, 0xc1, 0xe3, 0xfa,
  	0xfb, 0x03, 0x3b, 0xfb, 0xe0, 0x63, 0x63, 0xe3, 0xe1, 0xfb, 0x3a, 0x03, 0xfb, 0xfa, 0x0a, 0x0b,
  	0x0a, 0x0a, 0x0a, 0x6e, 0x14, 0x74, 0xc5, 0x80, 0xa2, 0xf3, 0xfc, 0x3f, 0x0f, 0x96, 0x15, 0xdd,
  	0xdd, 0xdb, 0xcb, 0x63, 0xef, 0xae, 0x03, 0x87, 0x37, 0x8c, 0xf7, 0x67, 0x9f, 0x46, 0xf0, 0xb0,
  	0x0f, 0xe2, 0x8e, 0x03, 0x9f, 0xfd, 0xef, 0xe2, 0x77, 0x5f, 0x3f, 0x99, 0x88, 0x18, 0x3e, 0xb8,
  	0x59, 0xbf, 0xf7, 0x70, 0x90, 0x9c, 0x29, 0xc1, 0x79, 0x7b, 0x8c, 0xc0, 0x00, 0x1f, 0xdf, 0xc7,
  	0x03, 0x80, 0x1f, 0xdf, 0xc0, 0xc0, 0x83, 0x87, 0x8e, 0xd8, 0xd8, 0x9c, 0x8f, 0x07, 0x80, 0x00,
  	0xc0, 0x40, 0x00, 0x06, 0x0f, 0xdb, 0x99, 0x19, 0xcc, 0x84, 0x80, 0x80, 0x1f, 0xcf, 0xc0, 0xc1,
  	0x87, 0x8f, 0x98, 0xd8, 0x98, 0x9c, 0x8e, 0x84, 0x40, 0x0f, 0xdf, 0x8f, 0x07, 0x83, 0xc0, 0x1f,
  	0x1f, 0x00, 0xc0, 0xc0, 0xc3, 0xcf, 0x9e, 0x0f, 0x03, 0x00, 0xc0, 0x40, 0x1f, 0x9f, 0x80, 0x80,
  	0x80, 0xc0, 0x00, 0x71, 0xe3, 0x71, 0x38, 0x39, 0x75, 0x77, 0x77, 0x74, 0x44, 0x47, 0x03, 0xfe,
  	0xa5, 0x23, 0x1d, 0x1c, 0xa7, 0xd5, 0x51, 0xf5, 0x76, 0xb3, 0xdf, 0xb7, 0x7c, 0xfe, 0xde, 0xf7,
  	0xe6, 0x22, 0x3a, 0x93, 0xff, 0xfb, 0xe6, 0x20, 0x8e, 0xdf, 0x0e, 0x9f, 0xde, 0x68, 0xf2, 0x5b,
  	0xb7, 0xbe, 0x63, 0x5f, 0x13, 0x07, 0x36, 0xbe, 0x8e, 0x53, 0xd3, 0xaf, 0xc6, 0xd6, 0xda, 0xfe,
  	0x53, 0x41, 0xa1, 0xfb, 0x6b, 0xef, 0x8e, 0xda, 0xff, 0xff, 0xff, 0xaf, 0x79, 0x18, 0x98, 0xf7,
  	0x8f, 0x85, 0xb9, 0x88, 0xed, 0xf7, 0x73, 0x33, 0x7f, 0x66, 0xff, 0xed, 0xa9, 0x80, 0x27, 0xa7,
  	0x45, 0x4f, 0x67, 0x17, 0x0f, 0xae, 0x3f, 0x6c, 0xe0, 0xe0, 0xc4, 0x1d, 0x37, 0x7f, 0xec, 0x20,
  	0xce, 0x84, 0xa7, 0xc7, 0x9e, 0xfc, 0xfd, 0xf3, 0x80, 0xcc, 0xd0, 0x8c, 0xdd, 0x5b, 0x02, 0x07,
  	0x7f, 0xff, 0x6b, 0x4b, 0xef, 0x3f, 0x5f, 0x6f, 0xee, 0xe2, 0xe3, 0x00, 0xf0, 0x87, 0x91, 0xeb,
  	0xc3, 0xc1, 0x01, 0x7e, 0x7f, 0xee, 0xee, 0xc1, 0x7c, 0x3b, 0xba, 0x86, 0xe7, 0x13, 0xd9, 0x70,
  	0x7f, 0x61, 0x80, 0x7a, 0xbb, 0x93, 0x23, 0x7b, 0xa7, 0xda, 0x1a, 0xd8, 0xdb, 0xc0, 0xd3, 0x7a,
  	0x7e, 0x12, 0xda, 0x28, 0x72, 0x52, 0x19, 0xa9, 0xff, 0x4e, 0xec, 0x62, 0x7c, 0x66, 0x8d, 0xc1,
  	0xbb, 0x1b, 0x1c, 0x49, 0x9e, 0x2e, 0x25, 0x40, 0x71, 0x43, 0xf2, 0xfd, 0xbc, 0x37, 0xa1, 0x24,
  	0x69, 0x99, 0x91, 0xcf, 0x80, 0xf9, 0x16, 0x3a, 0x38, 0xf1, 0xd1, 0x31, 0x7e, 0x9b, 0x40, 0xf9,
  	0x79, 0x02, 0x3b, 0xf4, 0x40, 0x4f, 0xac, 0xe2, 0xe7, 0x25, 0x81, 0xec, 0x0d, 0x3a, 0x2b, 0x2c,
  	0x42, 0x0f, 0x67, 0xdb, 0xf3, 0xc1, 0x09, 0xfd, 0x51, 0x4f, 0xee, 0xf0, 0x85, 0x8f, 0xdf, 0x80,
  	0x84, 0x4d, 0x0f, 0x84, 0x3e, 0x5c, 0x6b, 0x36, 0x75, 0x0f, 0xa6, 0x73, 0x2c, 0xdc, 0x47, 0x3f,
  	0xb8, 0x18, 0x3f, 0x9f, 0x33, 0x31, 0x8f, 0x8d, 0x77, 0x77, 0x67, 0xe1, 0xbd, 0x79, 0xcb, 0x37,
  	0x08, 0x42, 0x07, 0x78, 0x3b, 0x7f, 0x7d, 0x3d, 0xbc, 0xbf, 0x78, 0x38, 0xc3, 0xa8, 0x8b, 0x9c,
  	0x8c, 0x3f, 0xf8, 0xf6, 0xbf, 0x3e, 0x8e, 0xcf, 0xf9, 0x60, 0x65, 0xef, 0xce, 0x22, 0xff, 0xdd,
  	0x9f, 0x34, 0xb3, 0xb0, 0x40, 0xda, 0xfb, 0xff, 0xfc, 0xee, 0xec, 0x5c, 0x35, 0xa0, 0x3d, 0xbe,
  	0x13, 0x73, 0xe7, 0x8f, 0xef, 0xdb, 0xc7, 0xf3, 0x1b, 0x98, 0x5d, 0x3d, 0x28, 0xc1, 0xef, 0x71,
  	0xfc, 0xde, 0xde, 0x3d, 0xf0, 0xf7, 0xf5, 0x13, 0x3e, 0xe5, 0xfd, 0xe1, 0x01, 0x84, 0x9e, 0xff,
  	0xcf, 0xcf, 0x60, 0x6f, 0xef, 0xbb, 0xb1, 0x42, 0x23, 0xed, 0x0b, 0xd8, 0xdc, 0x0e, 0x13, 0x19,
  	0x17, 0x7d, 0x3e, 0x06, 0x00, 0xc0, 0x52, 0xf1, 0xf2, 0x3c, 0x60, 0x78, 0x3b, 0xf2, 0xf2, 0xb2,
  	0xb5, 0x9f, 0x9f, 0x27, 0x6a, 0x38, 0x3d, 0x3d, 0x08, 0x8c, 0xe6, 0xac, 0x25, 0x67, 0x37, 0xe4
  };
  // 'frame_5_delay-0', 128x64px
  const uint8_t frame5[] = {  	0x8e, 0xf7, 0xf7, 0x06, 0x6f, 0xdf, 0x42, 0xed, 0x82, 0x7b, 0xd1, 0x31, 0xf2, 0xf3, 0xc1, 0x81,
  	0x49, 0x7e, 0x6b, 0x71, 0xf9, 0xf1, 0xe9, 0xc3, 0x8b, 0x27, 0x3c, 0x68, 0x9c, 0x03, 0xa3, 0xc5,
  	0xf9, 0x38, 0x6f, 0x6f, 0xff, 0x86, 0xa3, 0xc6, 0x96, 0x86, 0x0f, 0xde, 0x76, 0x1e, 0x87, 0x1f,
  	0x85, 0x1d, 0xf5, 0x3e, 0xc0, 0x70, 0xd1, 0xf4, 0xa4, 0x42, 0x5f, 0x4c, 0x78, 0x1a, 0xc3, 0xfb,
  	0xbd, 0xe0, 0x90, 0xf5, 0xf1, 0x7b, 0xae, 0xe1, 0xe5, 0x9d, 0x6e, 0x1f, 0xd2, 0x6a, 0x10, 0x8c,
  	0x5e, 0x7a, 0xdf, 0x04, 0x43, 0x91, 0xb7, 0x35, 0x6d, 0xef, 0xad, 0xe7, 0xd7, 0x0e, 0x0e, 0xd7,
  	0x5f, 0x59, 0x53, 0xdc, 0xfb, 0xd2, 0xf8, 0x48, 0xe0, 0x42, 0xbf, 0xfe, 0xc1, 0x01, 0x80, 0x80,
  	0xa6, 0xe3, 0xe3, 0x2f, 0x29, 0x72, 0x86, 0x82, 0x07, 0x37, 0x74, 0xd1, 0x33, 0xbc, 0xbf, 0xae,
  	0x9b, 0x3f, 0xff, 0x9f, 0xfe, 0xff, 0xa1, 0x1f, 0x0d, 0xd1, 0x0a, 0xdf, 0xcb, 0xc7, 0xd9, 0xc1,
  	0x51, 0x63, 0x40, 0x7e, 0x01, 0xfc, 0xfe, 0x9d, 0xff, 0xdf, 0x3e, 0xac, 0xfc, 0xe6, 0xfa, 0x33,
  	0x33, 0x21, 0x50, 0x78, 0xbe, 0x7e, 0x7d, 0x37, 0x7f, 0x3e, 0xa3, 0xd0, 0xeb, 0x6e, 0xa3, 0x83,
  	0x0f, 0x9f, 0x04, 0xbd, 0xfe, 0x3d, 0xdd, 0xf9, 0x81, 0x7b, 0xfa, 0xf6, 0xfe, 0x12, 0xd7, 0xff,
  	0xc1, 0xec, 0x1f, 0x7e, 0x1e, 0xf3, 0xcf, 0xf9, 0xfc, 0xfe, 0x87, 0x7f, 0x6e, 0x8b, 0x80, 0x0e,
  	0x67, 0x1c, 0xff, 0xf1, 0x31, 0x37, 0x33, 0x16, 0x3e, 0x1f, 0x4f, 0xdf, 0xdf, 0xef, 0x41, 0xd5,
  	0x61, 0x6f, 0xd1, 0xe1, 0x0d, 0x1d, 0xdf, 0xee, 0x9a, 0xe3, 0x5a, 0xde, 0x7f, 0xbb, 0xdb, 0x7f,
  	0xbb, 0x3f, 0xfb, 0x83, 0x80, 0x94, 0x19, 0x09, 0x99, 0x2a, 0x7e, 0xf6, 0xfe, 0xfb, 0x37, 0x63,
  	0xb9, 0xbf, 0xb7, 0xdf, 0x3e, 0x8f, 0xc6, 0x0f, 0xbc, 0x5b, 0x73, 0xe2, 0xf1, 0xd7, 0x61, 0xd8,
  	0xdf, 0xfb, 0x48, 0xf8, 0xcf, 0xef, 0xcb, 0x07, 0x7f, 0x6f, 0xc1, 0x6f, 0x67, 0x7c, 0xeb, 0xb3,
  	0x00, 0x22, 0x6e, 0x9c, 0x0f, 0x03, 0x35, 0x2f, 0x3c, 0xc9, 0xc3, 0x06, 0x97, 0xef, 0xfe, 0xf3,
  	0x43, 0x13, 0xd0, 0xc7, 0x2f, 0x78, 0x7a, 0xf7, 0xe4, 0xb8, 0xfb, 0xec, 0x78, 0xde, 0x03, 0x73,
  	0x33, 0xb0, 0x3f, 0xef, 0x3f, 0xf3, 0xfc, 0xfd, 0xff, 0xc0, 0xc0, 0x96, 0xf8, 0xc7, 0xc7, 0x12,
  	0x1f, 0x39, 0x1f, 0x9f, 0x84, 0xdc, 0x3c, 0xa4, 0xb7, 0xb6, 0x00, 0x33, 0xf9, 0xde, 0x9e, 0x8f,
  	0xcf, 0xf4, 0xf9, 0xfd, 0xbe, 0x0e, 0xc1, 0xd3, 0x79, 0x5f, 0x8f, 0xfd, 0x1e, 0x5f, 0x6c, 0xef,
  	0xf7, 0x7f, 0x7f, 0x7e, 0x7a, 0xbf, 0x1f, 0xbf, 0xbe, 0xde, 0x5f, 0x30, 0x02, 0x73, 0xff, 0xdd,
  	0xb0, 0xf0, 0x4e, 0x9f, 0x67, 0xf7, 0x8e, 0x37, 0x87, 0x03, 0xee, 0xef, 0x63, 0xcb, 0xdb, 0xdd,
  	0xdd, 0x15, 0x96, 0x2f, 0x3f, 0xfc, 0xf3, 0xa2, 0x80, 0xc5, 0x74, 0x94, 0x02, 0xfa, 0xfa, 0x02,
  	0xc3, 0xe2, 0xfa, 0xfb, 0x03, 0x02, 0xc3, 0xf1, 0x7b, 0x1b, 0x0b, 0x38, 0xf3, 0xe3, 0x03, 0x03,
  	0x02, 0x03, 0x01, 0x21, 0x31, 0x18, 0x0a, 0x98, 0xf3, 0x60, 0x03, 0x00, 0xf8, 0xfa, 0x03, 0x80,
  	0xe1, 0xf3, 0x18, 0x88, 0x8b, 0xf8, 0xfa, 0xfb, 0x00, 0xf2, 0xf9, 0xf3, 0x83, 0xc1, 0xe2, 0xfa,
  	0xfa, 0x01, 0x3a, 0xf8, 0xe2, 0x63, 0x63, 0xe3, 0xe1, 0xfb, 0x38, 0x00, 0xfb, 0xfb, 0x0b, 0x09,
  	0x08, 0x0b, 0x09, 0xf3, 0xf3, 0x75, 0xc7, 0xec, 0x43, 0xcf, 0xef, 0xf5, 0xb7, 0xfe, 0xfd, 0xfd,
  	0x78, 0x78, 0x3b, 0x13, 0x70, 0x3f, 0x3c, 0xdc, 0x51, 0xf7, 0xff, 0xff, 0xf8, 0xc8, 0x10, 0x98,
  	0xf7, 0xde, 0x9e, 0x7c, 0xb7, 0xdf, 0xb3, 0x76, 0xf5, 0x51, 0xd5, 0xa7, 0x1c, 0x1d, 0x23, 0xa5,
  	0xfe, 0x03, 0x61, 0x44, 0x74, 0x77, 0x77, 0x75, 0x39, 0x28, 0x71, 0xe3, 0x41, 0x1f, 0xdf, 0x87,
  	0x83, 0x80, 0x9f, 0x5f, 0x40, 0xc0, 0x03, 0x07, 0x0e, 0x98, 0xd8, 0xdc, 0xcf, 0xc7, 0x00, 0x00,
  	0x00, 0xc0, 0x80, 0x06, 0x8f, 0xdb, 0x19, 0x59, 0x8c, 0x84, 0x80, 0x80, 0xdf, 0x8f, 0x80, 0x81,
  	0xc7, 0xcf, 0xd8, 0x58, 0x98, 0x9c, 0x8e, 0xc4, 0x00, 0x8f, 0xdf, 0x0f, 0x07, 0x83, 0x00, 0xdf,
  	0x1f, 0x80, 0x00, 0x80, 0x83, 0xcf, 0xde, 0x8f, 0x83, 0x80, 0xc0, 0xc0, 0xdf, 0x1f, 0x80, 0x00,
  	0xc0, 0xc0, 0x00, 0x40, 0xc0, 0x8c, 0x7b, 0x79, 0x61, 0x29, 0x1c, 0x90, 0x70, 0xf7, 0xbf, 0x59,
  	0xb8, 0x3e, 0x18, 0x88, 0x99, 0x3f, 0x5f, 0x77, 0xe2, 0xef, 0xfd, 0x1f, 0x07, 0x8e, 0xe2, 0x2f,
  	0x70, 0xd9, 0x13, 0xe7, 0x86, 0xba, 0x3b, 0x7c, 0xc1, 0xee, 0xee, 0x7f, 0x7e, 0x01, 0xc1, 0xc1,
  	0xeb, 0x91, 0x87, 0xf0, 0x00, 0xe3, 0xe2, 0xee, 0x6f, 0x5f, 0x3f, 0xef, 0x4b, 0x6b, 0xff, 0x7f,
  	0x07, 0x02, 0x5f, 0xdd, 0x8c, 0xd0, 0xcc, 0xc0, 0xf3, 0xff, 0xfc, 0x9e, 0xc7, 0xa7, 0x84, 0xce,
  	0x24, 0xec, 0x7f, 0x37, 0x1d, 0xc4, 0xe0, 0xe0, 0x6c, 0x3f, 0xae, 0x1f, 0x37, 0x67, 0x6f, 0x45,
  	0xa7, 0x27, 0x80, 0xa9, 0xed, 0xff, 0x66, 0x7f, 0x33, 0x73, 0xf7, 0xed, 0x88, 0xb9, 0x85, 0x8f,
  	0xf7, 0x98, 0x18, 0x79, 0xef, 0xff, 0xff, 0xff, 0xda, 0x8e, 0xef, 0x5b, 0xfb, 0xa9, 0x61, 0x53,
  	0xfe, 0xda, 0xd6, 0xd6, 0xaf, 0xd3, 0x53, 0x9e, 0xfe, 0x76, 0x07, 0x13, 0x5f, 0x63, 0xbf, 0xb7,
  	0x5b, 0xf2, 0x68, 0xde, 0x9f, 0x0e, 0xdf, 0x8e, 0x20, 0xe6, 0xff, 0xff, 0x93, 0x3a, 0x22, 0xe6,
  	0x37, 0xcb, 0x79, 0xbd, 0xe1, 0xe7, 0x77, 0x77, 0x9d, 0x9f, 0x31, 0x33, 0x9f, 0x3f, 0x18, 0xb8,
  	0xbf, 0x47, 0xfc, 0x24, 0x70, 0xa6, 0x0f, 0x7d, 0x36, 0x6b, 0x5e, 0x3e, 0x84, 0x4f, 0x4d, 0x84,
  	0x80, 0xdf, 0x8f, 0x85, 0xf0, 0xee, 0x4f, 0x51, 0xfd, 0x09, 0xc1, 0xf3, 0xdb, 0x67, 0x0f, 0x42,
  	0x2c, 0x2f, 0x3a, 0x0d, 0xec, 0x85, 0x25, 0xe7, 0xe2, 0xac, 0x4f, 0x48, 0xfc, 0x3f, 0x02, 0x7d,
  	0xf9, 0xc1, 0x9f, 0x7f, 0x31, 0xd1, 0xf1, 0x38, 0x3a, 0x06, 0xf9, 0x80, 0xcf, 0x99, 0x99, 0x49,
  	0x64, 0xa1, 0x37, 0xbc, 0xfd, 0xf2, 0x43, 0x71, 0x40, 0x25, 0x2e, 0x9e, 0x49, 0x1c, 0x1b, 0xb3,
  	0xc1, 0x8d, 0x66, 0x7c, 0x62, 0xee, 0x4e, 0xfd, 0xa9, 0x19, 0x72, 0x72, 0x28, 0xda, 0x12, 0x7e,
  	0x7a, 0xd3, 0xc0, 0xdb, 0xd8, 0x1a, 0xda, 0xa7, 0x7b, 0x23, 0x93, 0xbb, 0x7a, 0x80, 0x61, 0x7f,
  	0xe4, 0x37, 0x67, 0x25, 0xac, 0xe6, 0x9c, 0x0c, 0x3d, 0x3d, 0x38, 0x6a, 0xa7, 0x9f, 0x9f, 0xb5,
  	0xb2, 0xfa, 0xf2, 0x3b, 0x78, 0x60, 0x3c, 0xf6, 0xd1, 0x52, 0xc0, 0x00, 0x06, 0x3e, 0x7d, 0x17,
  	0x19, 0x13, 0x0e, 0xdc, 0xd0, 0x0b, 0xed, 0x23, 0xc2, 0xb1, 0xbb, 0xef, 0x6f, 0x60, 0xcf, 0xcf,
  	0xff, 0x9e, 0x84, 0x01, 0xe1, 0xfd, 0xe5, 0x3e, 0x13, 0xfd, 0xf7, 0xf0, 0xbd, 0xde, 0xde, 0xfc,
  	0x79, 0xef, 0xc1, 0x28, 0x3d, 0x5d, 0x98, 0x1b, 0xf3, 0xc7, 0xdb, 0xef, 0x8f, 0xe7, 0x73, 0x13,
  	0xbe, 0x7d, 0xa0, 0x3d, 0x5c, 0xec, 0xee, 0xfc, 0xff, 0xff, 0xde, 0x40, 0xb0, 0xb3, 0x34, 0x9f,
  	0xdd, 0xff, 0x23, 0xce, 0xef, 0x65, 0x60, 0xf9, 0xcf, 0x8e, 0x3e, 0xbf, 0xf6, 0xfc, 0x1f, 0x8c,
  	0x9c, 0x8b, 0xa8, 0xc3, 0x38, 0x78, 0xbf, 0xbc, 0x3d, 0x7d, 0x7f, 0x3b, 0x78, 0x07, 0x42, 0x08
  };

  const uint8_t *gif_frames[] = {frame0, frame1, frame2, frame3, frame4, frame5};

  const char *text1 = "You built me but more than that, you cared for me";
  // Type text1 starting at (0,0) with a 100ms delay between characters
  OLED_TypeText(0, 0, text1, 100);

  while (1) {
      for (int i = 0; i < 6; i++) {
          OLED_ShowFrame(gif_frames[i]);
          HAL_Delay(100); // Frame delay
      }
  }

  /* USER CODE END 2 */

  /* Infinite loop */
  while (1)
  {

    /* USER CODE BEGIN 3 */
	/* ----- Start: Sensor reading ----- */
	//trigger distance measurement.

	if (!(ticksElapsed % ticksUs)) {
		motion_sen_us_trig();
	}

	//motion_sen_init
	motion_sen_read_accel();
	motion_sen_read_gyroZ();
	motion_sen_read_irDist();

	//sprintf(clear, "L:%09.6f     R:%09.6f     US:%09.6f\0", sensors.irDist[0],sensors.irDist[1],sensors.usDist);
	//OLED_ShowString(0, 10, clear);
	//OLED_Refresh_Gram();

	/* ----- End: Sensor reading ----- */

	/* ----- Start: Get next command (if any) ----- */ //Set the Command to drive
	if (cmd == NULL) {
//		sprintf(hello,"D: %d\0", distTrack);
//		OLED_ShowString(10, 20, hello);
//		OLED_Refresh_Gram();
		Command *peek = commands_peek();
//		Command *peek;
		if (!ticksDelay || (peek != NULL && peek->opType != DRIVE)) {
			cmd = commands_pop();

			if (cmd != NULL) {
				//perform command setup based on
				switch (cmd->opType) {
					case DRIVE:
						estDistOld = 0;
						estAngle = 0;
						motor_setDrive(cmd->dir, cmd->speed);
						if (cmd->dir != 0) {
							distTarget = cmd->val;
							distDiff = DIST_DIFF_DEFAULT;
							brakingDist = (cmd->distType == TARGET
								? MOTOR_BRAKING_DIST_CM_TARGET
								: MOTOR_BRAKING_DIST_CM_AWAY
							) * cmd->speed / 100;

							angleToSteer = cmd->angleToSteer;
							servo_setAngle(angleToSteer);
							if (angleToSteer != 0) {
								rBack = get_turning_r_back_cm(angleToSteer);
								//rBack = get_turning_r_steer_cm(angleToSteer);
								rRobot = get_turning_r_robot_cm(angleToSteer);
								if (cmd->distType == TARGET) {
									distTarget = abs_float(get_arc_length(cmd->val, rBack));
								}
							} else {
								rBack = 0;
								rRobot = 0;
								wTarget = 0;
							}

							//if (angleToSteer == 35) motor_freewheel(1);  // Freewheel right motor
							//else if (angleToSteer == -35) motor_freewheel(-1);  // Freewheel left motor
							//else motor_setDrive(cmd->dir, cmd->speed);

						} else {
							commands_end(&huart3, cmd);
							cmd = NULL;
						}
						break;

					case INFO_DIST:
					    shouldTrackDist = !shouldTrackDist;
					    if (shouldTrackDist) {
					        distTrack = 0;
					    } else {
					        free(cmd->str);
					        // Format response according to protocol: "Dxx.xx\n"
					        cmd->str_size = 8;  // "Dxx.xx\n" + null terminator
					        cmd->str = malloc(cmd->str_size);
					        snprintf(cmd->str, cmd->str_size, "D%6.2f\n", distTrack);

					        // Send via standard command completion
					        shouldTrackDist = 0;
					        distTrack = 0;
					    }
					    commands_end(&huart3, cmd);
					    cmd = NULL;
					    break;
					case INFO_MARKER:
						commands_end(&huart3, cmd);
						cmd = NULL;
						break;
					case TURN_IN_PLACE: {
					    // Set motors to turn in place
					    motor_setDifferential(1, cmd->speed, -1, cmd->speed);
						angleToSteer = cmd->angleToSteer;
						servo_setAngle(angleToSteer);
					    // Reset angle tracking
					    estAngle = 0;
					    float target_angle = cmd->val;  // From command

					    // Track angle using gyro
					    while (fabs(estAngle) < fabs(target_angle)) {
					        float wGyro = sensors.gyroZ;  // Get angular velocity
					        estAngle += wGyro * MS_FRAME; // Integrate over time
					        HAL_Delay(MS_FRAME);
					    }

					    // Stop after completing turn
					    motor_setDrive(0, 0);
					    commands_end(&huart3, cmd);
					    cmd = NULL;
					    break;
					}
				}
			}
		} else {
			peek = commands_peek_next_drive();
			if (peek != NULL) {
				servo_setAngle(peek->angleToSteer);
				if (ticksDelay > 0) ticksDelay--;
			}
		}
	}

	/* ----- End: Get next command (if any) ----- */

	/* ----- Start: Command Control Loop ----- */ //When running the commands
	if (cmd != NULL && cmd->dir != 0) {
		//calculate distance.
		motorDist = motor_getDist();
		estDist = cmd->dir * dist_get_cm(MS_FRAME, sensors.accel[1], motorDist);

		//estimate current speed.
		float estSpeed = (estDist - estDistOld) / MS_FRAME;
		estDistOld = estDist;

		//calculate difference in angular velocity.
		float wGyro;
		wGyro = cmd->dir * sensors.gyroZ;

		if (rBack != 0) {
			wTarget = get_w_ms(estSpeed, rBack);
		}
		else wTarget = 0;
		wDiff = (wGyro - wTarget); //gyro is flipped when going backwards.

		if (cmd->angleToSteer != 0) wDiff = 0;

		float angleDiff = wGyro * MS_FRAME;
		//if(!((angleDiff < GYRO_HPF_FREQ + 0.03) && (angleDiff > GYRO_HPF_FREQ - 0.03)));
		//else angleDiff = 0;
		if (cmd->angleToSteer < 0) angleDiff = -angleDiff;
		estAngle += angleDiff;
		distDiffOld = distDiff;

		uint8_t shouldEndIR = 0;

		switch (cmd->distType) {
			case TARGET:
				if (rBack != 0) {
					distDiff = get_arc_length(cmd->val - estAngle, abs_float(rBack));
				} else {
					distDiff = distTarget - estDist;
				}
				break;
			case STOP_AWAY:
				if (usCaptureComplete) { //This is glitchy I should change this soon
					distDiff = (sensors.usDist - cmd->val) * cmd->dir;
				}
				break;
			case STOP_L:
			case STOP_R:
			case STOP_L_LESS:
			case STOP_R_LESS:
				uint8_t i = (cmd->distType == STOP_L || cmd->distType == STOP_L_LESS) ? 0 : 1;
				float irVal = sensors.irDist[i];
				float cmdVal = cmd->val;
				if (cmdVal < 0) cmdVal = -cmdVal;

				if(cmd->distType == STOP_L || cmd->distType == STOP_R)
					shouldEndIR = irVal > cmdVal ? 1 : 0;
				else
					shouldEndIR = irVal < cmdVal ? 1 : 0;
				distDiff = DIST_DIFF_DEFAULT;
				break;
			default:
				distDiff = DIST_DIFF_DEFAULT;
				break;
		}

		Command *next = commands_peek();
		if (next != NULL && next->opType == DRIVE && commands_type_match(cmd, next)) {
			//absorb next command into current command.
			next = commands_pop();

			switch (next->distType) {
				case TARGET:
					cmd->val += next->val;
					break;
				case STOP_AWAY:
				case STOP_L:
				case STOP_R:
				case STOP_L_LESS:
				case STOP_R_LESS:
					cmd->val = next->val;
					break;
			}

			commands_end(&huart3, next);
		}

		next = commands_peek_next_drive();
		float queueAngle = next != NULL ? next->angleToSteer : 0;
		float queueAngleDiff = abs_float(queueAngle - cmd->angleToSteer);
		uint8_t shouldBrake = cmd->distType == STOP_AWAY ? 1 : next != NULL ? next->dir != cmd->dir
					|| queueAngleDiff > SERVO_WIDTH			//too large a turn.
					|| queueAngle * cmd->angleToSteer < 0	//opposite direction.
				: 1;
		uint8_t turnSpeed = next != NULL ? min_uint8(BRAKE_SPEED, next->speed) : BRAKE_SPEED;

		//motor correction.
		motor_pwmCorrection(
			wDiff, rBack, distDiff,
			brakingDist, cmd->distType,
			shouldBrake ? 0 : turnSpeed
		);
		//if (cmd->angleToSteer == 35) motor_freewheel(1);  // Freewheel right motor
		//else if (cmd->angleToSteer == -35) motor_freewheel(-1);  // Freewheel left motor

		float timeLeft = estSpeed > 0 ? distDiff / estSpeed : 1e10;

		uint8_t shouldEnd = 0;
		if (!shouldBrake && !(ticksElapsed % ticksServo)) {
			//turn a small angle every SERVO_TURN_PERIOD ms.
			float diff = abs_float(queueAngle - angleToSteer);

			if (timeLeft < (SERVO_TURN_PERIOD) * (diff / SERVO_TURN_STEP)) {
				//should increment.
				float step = min_float(SERVO_TURN_STEP, diff);
				if (queueAngle < angleToSteer) step = -step;
				angleToSteer += step;
				servo_setAngle(angleToSteer);

				if (diff < SERVO_TURN_STEP) {
					shouldEnd = 1;
				}
			}
		}

		float absDistDiff = abs_float(distDiff),
				absDistDiffChange = abs_float(distDiff - distDiffOld);
		uint8_t shouldTick = (shouldBrake
				&& absDistDiff < 1 && absDistDiffChange < 0.2)	//no change in motion.
				|| absDistDiff < 0.05;								//error threshold satisfied.
		ticksES = shouldTick ? ticksES + 1 : 0;

		shouldEnd |= ticksES >= TICKS_ES_MAX	//minimum error threshold ticks met.
					|| distDiff < 0.9; 		//prevent overshoot.
		shouldEnd |= shouldEndIR;
		if (shouldEnd) {
			//target achieved; move to next command.
			ticksES = 0;
			commands_end(&huart3, cmd);
			cmd = NULL;

			servo_setAngle(queueAngle);
			if (shouldBrake) {
				ticksDelay = (SERVO_TURN_PERIOD / MS_FRAME) * (abs_float(queueAngle - angleToSteer) / SERVO_TURN_STEP) + 15;
				motor_setDrive(0, 0);
				dist_reset(0);
			} else dist_reset(estSpeed);

			//add estimated travel distance to tracking distance (if tracked).
			if (shouldTrackDist) distTrack += estDist;
		}
	}
	/* ----- End: Command Control Loop ----- */
	/* ----- Start: Paced Loop Control ----- */
	while (!newTick) {									//wait for new tick.
		/* ----- Start: Process Ring Buffer ----- */
		/* We use the down time for paced looping to process commands. */
		if (track_i != ring_i) {
			uint8_t c = ring_serial[track_i];
			buf_serial[buf_i++] = c;
			if (c == CMD_END) {
				commands_process(&huart3, buf_serial, buf_i);
				buf_i = 0;
			}

			serial_inc_ring(&track_i);
		}
		/* ----- End: Process Ring Buffer ----- */
	}
	newTick = 0;										//acknowledge flag.

	ticksElapsed = (ticksElapsed + 1) % ticksRefresh;	//refresh tick count.
	/* ----- End: Paced Loop Control ----- */
  }
  /* USER CODE END 3 */
}

void SystemClock_Config(void)
{
  RCC_OscInitTypeDef RCC_OscInitStruct = {0};
  RCC_ClkInitTypeDef RCC_ClkInitStruct = {0};

  /** Configure the main internal regulator output voltage
  */
  __HAL_RCC_PWR_CLK_ENABLE();
  __HAL_PWR_VOLTAGESCALING_CONFIG(PWR_REGULATOR_VOLTAGE_SCALE1);

  /** Initializes the RCC Oscillators according to the specified parameters
  * in the RCC_OscInitTypeDef structure.
  */
  RCC_OscInitStruct.OscillatorType = RCC_OSCILLATORTYPE_HSI;
  RCC_OscInitStruct.HSIState = RCC_HSI_ON;
  RCC_OscInitStruct.HSICalibrationValue = RCC_HSICALIBRATION_DEFAULT;
  RCC_OscInitStruct.PLL.PLLState = RCC_PLL_NONE;
  if (HAL_RCC_OscConfig(&RCC_OscInitStruct) != HAL_OK)
  {
    Error_Handler();
  }

  /** Initializes the CPU, AHB and APB buses clocks
  */
  RCC_ClkInitStruct.ClockType = RCC_CLOCKTYPE_HCLK|RCC_CLOCKTYPE_SYSCLK
                              |RCC_CLOCKTYPE_PCLK1|RCC_CLOCKTYPE_PCLK2;
  RCC_ClkInitStruct.SYSCLKSource = RCC_SYSCLKSOURCE_HSI;
  RCC_ClkInitStruct.AHBCLKDivider = RCC_SYSCLK_DIV1;
  RCC_ClkInitStruct.APB1CLKDivider = RCC_HCLK_DIV1;
  RCC_ClkInitStruct.APB2CLKDivider = RCC_HCLK_DIV1;

  if (HAL_RCC_ClockConfig(&RCC_ClkInitStruct, FLASH_LATENCY_0) != HAL_OK)
  {
    Error_Handler();
  }
}

static void MX_ADC1_Init(void)
{

  ADC_ChannelConfTypeDef sConfig = {0};

  /** Configure the global features of the ADC (Clock, Resolution, Data Alignment and number of conversion)
  */
  hadc1.Instance = ADC1;
  hadc1.Init.ClockPrescaler = ADC_CLOCK_SYNC_PCLK_DIV2;
  hadc1.Init.Resolution = ADC_RESOLUTION_12B;
  hadc1.Init.ScanConvMode = DISABLE;
  hadc1.Init.ContinuousConvMode = DISABLE;
  hadc1.Init.DiscontinuousConvMode = DISABLE;
  hadc1.Init.ExternalTrigConvEdge = ADC_EXTERNALTRIGCONVEDGE_NONE;
  hadc1.Init.ExternalTrigConv = ADC_SOFTWARE_START;
  hadc1.Init.DataAlign = ADC_DATAALIGN_RIGHT;
  hadc1.Init.NbrOfConversion = 1;
  hadc1.Init.DMAContinuousRequests = DISABLE;
  hadc1.Init.EOCSelection = ADC_EOC_SINGLE_CONV;
  if (HAL_ADC_Init(&hadc1) != HAL_OK)
  {
    Error_Handler();
  }

  /** Configure for the selected ADC regular channel its corresponding rank in the sequencer and its sample time.
  */
  sConfig.Channel = ADC_CHANNEL_11;
  sConfig.Rank = 1;
  sConfig.SamplingTime = ADC_SAMPLETIME_3CYCLES;
  if (HAL_ADC_ConfigChannel(&hadc1, &sConfig) != HAL_OK)
  {
    Error_Handler();
  }

}

static void MX_ADC2_Init(void)
{

  ADC_ChannelConfTypeDef sConfig = {0};

  /** Configure the global features of the ADC (Clock, Resolution, Data Alignment and number of conversion)
  */
  hadc2.Instance = ADC2;
  hadc2.Init.ClockPrescaler = ADC_CLOCK_SYNC_PCLK_DIV2;
  hadc2.Init.Resolution = ADC_RESOLUTION_12B;
  hadc2.Init.ScanConvMode = DISABLE;
  hadc2.Init.ContinuousConvMode = DISABLE;
  hadc2.Init.DiscontinuousConvMode = DISABLE;
  hadc2.Init.ExternalTrigConvEdge = ADC_EXTERNALTRIGCONVEDGE_NONE;
  hadc2.Init.ExternalTrigConv = ADC_SOFTWARE_START;
  hadc2.Init.DataAlign = ADC_DATAALIGN_RIGHT;
  hadc2.Init.NbrOfConversion = 1;
  hadc2.Init.DMAContinuousRequests = DISABLE;
  hadc2.Init.EOCSelection = ADC_EOC_SINGLE_CONV;
  if (HAL_ADC_Init(&hadc2) != HAL_OK)
  {
    Error_Handler();
  }

  /** Configure for the selected ADC regular channel its corresponding rank in the sequencer and its sample time.
  */
  sConfig.Channel = ADC_CHANNEL_12;
  sConfig.Rank = 1;
  sConfig.SamplingTime = ADC_SAMPLETIME_3CYCLES;
  if (HAL_ADC_ConfigChannel(&hadc2, &sConfig) != HAL_OK)
  {
    Error_Handler();
  }

}

static void MX_I2C1_Init(void)
{

  hi2c1.Instance = I2C1;
  hi2c1.Init.ClockSpeed = 400000;
  hi2c1.Init.DutyCycle = I2C_DUTYCYCLE_2;
  hi2c1.Init.OwnAddress1 = 0;
  hi2c1.Init.AddressingMode = I2C_ADDRESSINGMODE_7BIT;
  hi2c1.Init.DualAddressMode = I2C_DUALADDRESS_DISABLE;
  hi2c1.Init.OwnAddress2 = 0;
  hi2c1.Init.GeneralCallMode = I2C_GENERALCALL_DISABLE;
  hi2c1.Init.NoStretchMode = I2C_NOSTRETCH_DISABLE;
  if (HAL_I2C_Init(&hi2c1) != HAL_OK)
  {
    Error_Handler();
  }

}

static void MX_TIM1_Init(void)
{

  TIM_ClockConfigTypeDef sClockSourceConfig = {0};
  TIM_MasterConfigTypeDef sMasterConfig = {0};
  TIM_OC_InitTypeDef sConfigOC = {0};
  TIM_BreakDeadTimeConfigTypeDef sBreakDeadTimeConfig = {0};

  htim1.Instance = TIM1;
  htim1.Init.Prescaler = 5-1;
  htim1.Init.CounterMode = TIM_COUNTERMODE_UP;
  htim1.Init.Period = 64000-1;
  htim1.Init.ClockDivision = TIM_CLOCKDIVISION_DIV1;
  htim1.Init.RepetitionCounter = 0;
  htim1.Init.AutoReloadPreload = TIM_AUTORELOAD_PRELOAD_DISABLE;
  if (HAL_TIM_Base_Init(&htim1) != HAL_OK)
  {
    Error_Handler();
  }
  sClockSourceConfig.ClockSource = TIM_CLOCKSOURCE_INTERNAL;
  if (HAL_TIM_ConfigClockSource(&htim1, &sClockSourceConfig) != HAL_OK)
  {
    Error_Handler();
  }
  if (HAL_TIM_PWM_Init(&htim1) != HAL_OK)
  {
    Error_Handler();
  }
  sMasterConfig.MasterOutputTrigger = TIM_TRGO_RESET;
  sMasterConfig.MasterSlaveMode = TIM_MASTERSLAVEMODE_DISABLE;
  if (HAL_TIMEx_MasterConfigSynchronization(&htim1, &sMasterConfig) != HAL_OK)
  {
    Error_Handler();
  }
  sConfigOC.OCMode = TIM_OCMODE_PWM1;
  sConfigOC.Pulse = 0;
  sConfigOC.OCPolarity = TIM_OCPOLARITY_HIGH;
  sConfigOC.OCNPolarity = TIM_OCNPOLARITY_HIGH;
  sConfigOC.OCFastMode = TIM_OCFAST_DISABLE;
  sConfigOC.OCIdleState = TIM_OCIDLESTATE_RESET;
  sConfigOC.OCNIdleState = TIM_OCNIDLESTATE_RESET;
  if (HAL_TIM_PWM_ConfigChannel(&htim1, &sConfigOC, TIM_CHANNEL_1) != HAL_OK)
  {
    Error_Handler();
  }
  sBreakDeadTimeConfig.OffStateRunMode = TIM_OSSR_DISABLE;
  sBreakDeadTimeConfig.OffStateIDLEMode = TIM_OSSI_DISABLE;
  sBreakDeadTimeConfig.LockLevel = TIM_LOCKLEVEL_OFF;
  sBreakDeadTimeConfig.DeadTime = 0;
  sBreakDeadTimeConfig.BreakState = TIM_BREAK_DISABLE;
  sBreakDeadTimeConfig.BreakPolarity = TIM_BREAKPOLARITY_HIGH;
  sBreakDeadTimeConfig.AutomaticOutput = TIM_AUTOMATICOUTPUT_DISABLE;
  if (HAL_TIMEx_ConfigBreakDeadTime(&htim1, &sBreakDeadTimeConfig) != HAL_OK)
  {
    Error_Handler();
  }
  HAL_TIM_MspPostInit(&htim1);

}

static void MX_TIM2_Init(void)
{

  TIM_Encoder_InitTypeDef sConfig = {0};
  TIM_MasterConfigTypeDef sMasterConfig = {0};

  htim2.Instance = TIM2;
  htim2.Init.Prescaler = 0;
  htim2.Init.CounterMode = TIM_COUNTERMODE_UP;
  htim2.Init.Period = 65535;
  htim2.Init.ClockDivision = TIM_CLOCKDIVISION_DIV1;
  htim2.Init.AutoReloadPreload = TIM_AUTORELOAD_PRELOAD_DISABLE;
  sConfig.EncoderMode = TIM_ENCODERMODE_TI12;
  sConfig.IC1Polarity = TIM_ICPOLARITY_RISING;
  sConfig.IC1Selection = TIM_ICSELECTION_DIRECTTI;
  sConfig.IC1Prescaler = TIM_ICPSC_DIV1;
  sConfig.IC1Filter = 0;
  sConfig.IC2Polarity = TIM_ICPOLARITY_RISING;
  sConfig.IC2Selection = TIM_ICSELECTION_DIRECTTI;
  sConfig.IC2Prescaler = TIM_ICPSC_DIV1;
  sConfig.IC2Filter = 0;
  if (HAL_TIM_Encoder_Init(&htim2, &sConfig) != HAL_OK)
  {
    Error_Handler();
  }
  sMasterConfig.MasterOutputTrigger = TIM_TRGO_RESET;
  sMasterConfig.MasterSlaveMode = TIM_MASTERSLAVEMODE_DISABLE;
  if (HAL_TIMEx_MasterConfigSynchronization(&htim2, &sMasterConfig) != HAL_OK)
  {
    Error_Handler();
  }

}

static void MX_TIM3_Init(void)
{

  TIM_Encoder_InitTypeDef sConfig = {0};
  TIM_MasterConfigTypeDef sMasterConfig = {0};

  htim3.Instance = TIM3;
  htim3.Init.Prescaler = 0;
  htim3.Init.CounterMode = TIM_COUNTERMODE_UP;
  htim3.Init.Period = 65535;
  htim3.Init.ClockDivision = TIM_CLOCKDIVISION_DIV1;
  htim3.Init.AutoReloadPreload = TIM_AUTORELOAD_PRELOAD_DISABLE;
  sConfig.EncoderMode = TIM_ENCODERMODE_TI12;
  sConfig.IC1Polarity = TIM_ICPOLARITY_RISING;
  sConfig.IC1Selection = TIM_ICSELECTION_DIRECTTI;
  sConfig.IC1Prescaler = TIM_ICPSC_DIV1;
  sConfig.IC1Filter = 0;
  sConfig.IC2Polarity = TIM_ICPOLARITY_RISING;
  sConfig.IC2Selection = TIM_ICSELECTION_DIRECTTI;
  sConfig.IC2Prescaler = TIM_ICPSC_DIV1;
  sConfig.IC2Filter = 0;
  if (HAL_TIM_Encoder_Init(&htim3, &sConfig) != HAL_OK)
  {
    Error_Handler();
  }
  sMasterConfig.MasterOutputTrigger = TIM_TRGO_RESET;
  sMasterConfig.MasterSlaveMode = TIM_MASTERSLAVEMODE_DISABLE;
  if (HAL_TIMEx_MasterConfigSynchronization(&htim3, &sMasterConfig) != HAL_OK)
  {
    Error_Handler();
  }

}

static void MX_TIM4_Init(void)
{

  TIM_ClockConfigTypeDef sClockSourceConfig = {0};
  TIM_MasterConfigTypeDef sMasterConfig = {0};
  TIM_IC_InitTypeDef sConfigIC = {0};

  htim4.Instance = TIM4;
  htim4.Init.Prescaler = 16-1;
  htim4.Init.CounterMode = TIM_COUNTERMODE_UP;
  htim4.Init.Period = 65536-1;
  htim4.Init.ClockDivision = TIM_CLOCKDIVISION_DIV1;
  htim4.Init.AutoReloadPreload = TIM_AUTORELOAD_PRELOAD_DISABLE;
  if (HAL_TIM_Base_Init(&htim4) != HAL_OK)
  {
    Error_Handler();
  }
  sClockSourceConfig.ClockSource = TIM_CLOCKSOURCE_INTERNAL;
  if (HAL_TIM_ConfigClockSource(&htim4, &sClockSourceConfig) != HAL_OK)
  {
    Error_Handler();
  }
  if (HAL_TIM_IC_Init(&htim4) != HAL_OK)
  {
    Error_Handler();
  }
  sMasterConfig.MasterOutputTrigger = TIM_TRGO_RESET;
  sMasterConfig.MasterSlaveMode = TIM_MASTERSLAVEMODE_DISABLE;
  if (HAL_TIMEx_MasterConfigSynchronization(&htim4, &sMasterConfig) != HAL_OK)
  {
    Error_Handler();
  }
  sConfigIC.ICPolarity = TIM_INPUTCHANNELPOLARITY_RISING;
  sConfigIC.ICSelection = TIM_ICSELECTION_DIRECTTI;
  sConfigIC.ICPrescaler = TIM_ICPSC_DIV1;
  sConfigIC.ICFilter = 0;
  if (HAL_TIM_IC_ConfigChannel(&htim4, &sConfigIC, TIM_CHANNEL_1) != HAL_OK)
  {
    Error_Handler();
  }

}

static void MX_TIM6_Init(void)
{

  TIM_MasterConfigTypeDef sMasterConfig = {0};

  htim6.Instance = TIM6;
  htim6.Init.Prescaler = 16-1;
  htim6.Init.CounterMode = TIM_COUNTERMODE_UP;
  htim6.Init.Period = 65536-1;
  htim6.Init.AutoReloadPreload = TIM_AUTORELOAD_PRELOAD_DISABLE;
  if (HAL_TIM_Base_Init(&htim6) != HAL_OK)
  {
    Error_Handler();
  }
  sMasterConfig.MasterOutputTrigger = TIM_TRGO_RESET;
  sMasterConfig.MasterSlaveMode = TIM_MASTERSLAVEMODE_DISABLE;
  if (HAL_TIMEx_MasterConfigSynchronization(&htim6, &sMasterConfig) != HAL_OK)
  {
    Error_Handler();
  }

}

static void MX_TIM7_Init(void)
{

  TIM_MasterConfigTypeDef sMasterConfig = {0};

  htim7.Instance = TIM7;
  htim7.Init.Prescaler = 2-1;
  htim7.Init.CounterMode = TIM_COUNTERMODE_UP;
  htim7.Init.Period = 16000-1;
  htim7.Init.AutoReloadPreload = TIM_AUTORELOAD_PRELOAD_DISABLE;
  if (HAL_TIM_Base_Init(&htim7) != HAL_OK)
  {
    Error_Handler();
  }
  sMasterConfig.MasterOutputTrigger = TIM_TRGO_RESET;
  sMasterConfig.MasterSlaveMode = TIM_MASTERSLAVEMODE_DISABLE;
  if (HAL_TIMEx_MasterConfigSynchronization(&htim7, &sMasterConfig) != HAL_OK)
  {
    Error_Handler();
  }

}

static void MX_TIM8_Init(void)
{

  TIM_ClockConfigTypeDef sClockSourceConfig = {0};
  TIM_MasterConfigTypeDef sMasterConfig = {0};
  TIM_OC_InitTypeDef sConfigOC = {0};
  TIM_BreakDeadTimeConfigTypeDef sBreakDeadTimeConfig = {0};

  htim8.Instance = TIM8;
  htim8.Init.Prescaler = 0;
  htim8.Init.CounterMode = TIM_COUNTERMODE_UP;
  htim8.Init.Period = 7200-1;
  htim8.Init.ClockDivision = TIM_CLOCKDIVISION_DIV1;
  htim8.Init.RepetitionCounter = 0;
  htim8.Init.AutoReloadPreload = TIM_AUTORELOAD_PRELOAD_DISABLE;
  if (HAL_TIM_Base_Init(&htim8) != HAL_OK)
  {
    Error_Handler();
  }
  sClockSourceConfig.ClockSource = TIM_CLOCKSOURCE_INTERNAL;
  if (HAL_TIM_ConfigClockSource(&htim8, &sClockSourceConfig) != HAL_OK)
  {
    Error_Handler();
  }
  if (HAL_TIM_PWM_Init(&htim8) != HAL_OK)
  {
    Error_Handler();
  }
  sMasterConfig.MasterOutputTrigger = TIM_TRGO_RESET;
  sMasterConfig.MasterSlaveMode = TIM_MASTERSLAVEMODE_DISABLE;
  if (HAL_TIMEx_MasterConfigSynchronization(&htim8, &sMasterConfig) != HAL_OK)
  {
    Error_Handler();
  }
  sConfigOC.OCMode = TIM_OCMODE_PWM1;
  sConfigOC.Pulse = 0;
  sConfigOC.OCPolarity = TIM_OCPOLARITY_HIGH;
  sConfigOC.OCNPolarity = TIM_OCNPOLARITY_HIGH;
  sConfigOC.OCFastMode = TIM_OCFAST_DISABLE;
  sConfigOC.OCIdleState = TIM_OCIDLESTATE_RESET;
  sConfigOC.OCNIdleState = TIM_OCNIDLESTATE_RESET;
  if (HAL_TIM_PWM_ConfigChannel(&htim8, &sConfigOC, TIM_CHANNEL_1) != HAL_OK)
  {
    Error_Handler();
  }
  if (HAL_TIM_PWM_ConfigChannel(&htim8, &sConfigOC, TIM_CHANNEL_2) != HAL_OK)
  {
    Error_Handler();
  }
  sBreakDeadTimeConfig.OffStateRunMode = TIM_OSSR_DISABLE;
  sBreakDeadTimeConfig.OffStateIDLEMode = TIM_OSSI_DISABLE;
  sBreakDeadTimeConfig.LockLevel = TIM_LOCKLEVEL_OFF;
  sBreakDeadTimeConfig.DeadTime = 0;
  sBreakDeadTimeConfig.BreakState = TIM_BREAK_DISABLE;
  sBreakDeadTimeConfig.BreakPolarity = TIM_BREAKPOLARITY_HIGH;
  sBreakDeadTimeConfig.AutomaticOutput = TIM_AUTOMATICOUTPUT_DISABLE;
  if (HAL_TIMEx_ConfigBreakDeadTime(&htim8, &sBreakDeadTimeConfig) != HAL_OK)
  {
    Error_Handler();
  }
  HAL_TIM_MspPostInit(&htim8);

}

static void MX_USART3_UART_Init(void)
{

  huart3.Instance = USART3;
  huart3.Init.BaudRate = 115200;
  huart3.Init.WordLength = UART_WORDLENGTH_8B;
  huart3.Init.StopBits = UART_STOPBITS_1;
  huart3.Init.Parity = UART_PARITY_NONE;
  huart3.Init.Mode = UART_MODE_TX_RX;
  huart3.Init.HwFlowCtl = UART_HWCONTROL_NONE;
  huart3.Init.OverSampling = UART_OVERSAMPLING_16;
  if (HAL_UART_Init(&huart3) != HAL_OK)
  {
    Error_Handler();
  }

}

static void MX_GPIO_Init(void)
{
  GPIO_InitTypeDef GPIO_InitStruct = {0};

  /* GPIO Ports Clock Enable */
  __HAL_RCC_GPIOE_CLK_ENABLE();
  __HAL_RCC_GPIOC_CLK_ENABLE();
  __HAL_RCC_GPIOA_CLK_ENABLE();
  __HAL_RCC_GPIOD_CLK_ENABLE();
  __HAL_RCC_GPIOB_CLK_ENABLE();

  /*Configure GPIO pin Output Level */
  HAL_GPIO_WritePin(GPIOE, OLED_SCLK_Pin|OLED_SDIN_Pin|OLED_RESET__Pin|OLED_DATA_COMMAND__Pin, GPIO_PIN_RESET);

  /*Configure GPIO pin Output Level */
  HAL_GPIO_WritePin(GPIOA, MOTORA_IN2_Pin|MOTORA_IN1_Pin|MOTORB_IN1_Pin|MOTORB_IN2_Pin, GPIO_PIN_RESET);

  /*Configure GPIO pin Output Level */
  HAL_GPIO_WritePin(US_TRIG_GPIO_Port, US_TRIG_Pin, GPIO_PIN_RESET);

  /*Configure GPIO pins : OLED_SCLK_Pin OLED_SDIN_Pin OLED_RESET__Pin OLED_DATA_COMMAND__Pin */
  GPIO_InitStruct.Pin = OLED_SCLK_Pin|OLED_SDIN_Pin|OLED_RESET__Pin|OLED_DATA_COMMAND__Pin;
  GPIO_InitStruct.Mode = GPIO_MODE_OUTPUT_PP;
  GPIO_InitStruct.Pull = GPIO_NOPULL;
  GPIO_InitStruct.Speed = GPIO_SPEED_FREQ_LOW;
  HAL_GPIO_Init(GPIOE, &GPIO_InitStruct);

  /*Configure GPIO pins : MOTORA_IN2_Pin MOTORA_IN1_Pin MOTORB_IN1_Pin MOTORB_IN2_Pin */
  GPIO_InitStruct.Pin = MOTORA_IN2_Pin|MOTORA_IN1_Pin|MOTORB_IN1_Pin|MOTORB_IN2_Pin;
  GPIO_InitStruct.Mode = GPIO_MODE_OUTPUT_PP;
  GPIO_InitStruct.Pull = GPIO_NOPULL;
  GPIO_InitStruct.Speed = GPIO_SPEED_FREQ_LOW;
  HAL_GPIO_Init(GPIOA, &GPIO_InitStruct);

  /*Configure GPIO pin : BTN_USER_Pin */
  GPIO_InitStruct.Pin = BTN_USER_Pin;
  GPIO_InitStruct.Mode = GPIO_MODE_INPUT;
  GPIO_InitStruct.Pull = GPIO_PULLUP;
  HAL_GPIO_Init(BTN_USER_GPIO_Port, &GPIO_InitStruct);

  /*Configure GPIO pin : US_TRIG_Pin */
  GPIO_InitStruct.Pin = US_TRIG_Pin;
  GPIO_InitStruct.Mode = GPIO_MODE_OUTPUT_PP;
  GPIO_InitStruct.Pull = GPIO_NOPULL;
  GPIO_InitStruct.Speed = GPIO_SPEED_FREQ_LOW;
  HAL_GPIO_Init(US_TRIG_GPIO_Port, &GPIO_InitStruct);

}

void Error_Handler(void)
{
  __disable_irq();
  while (1)
  {
  }
}
